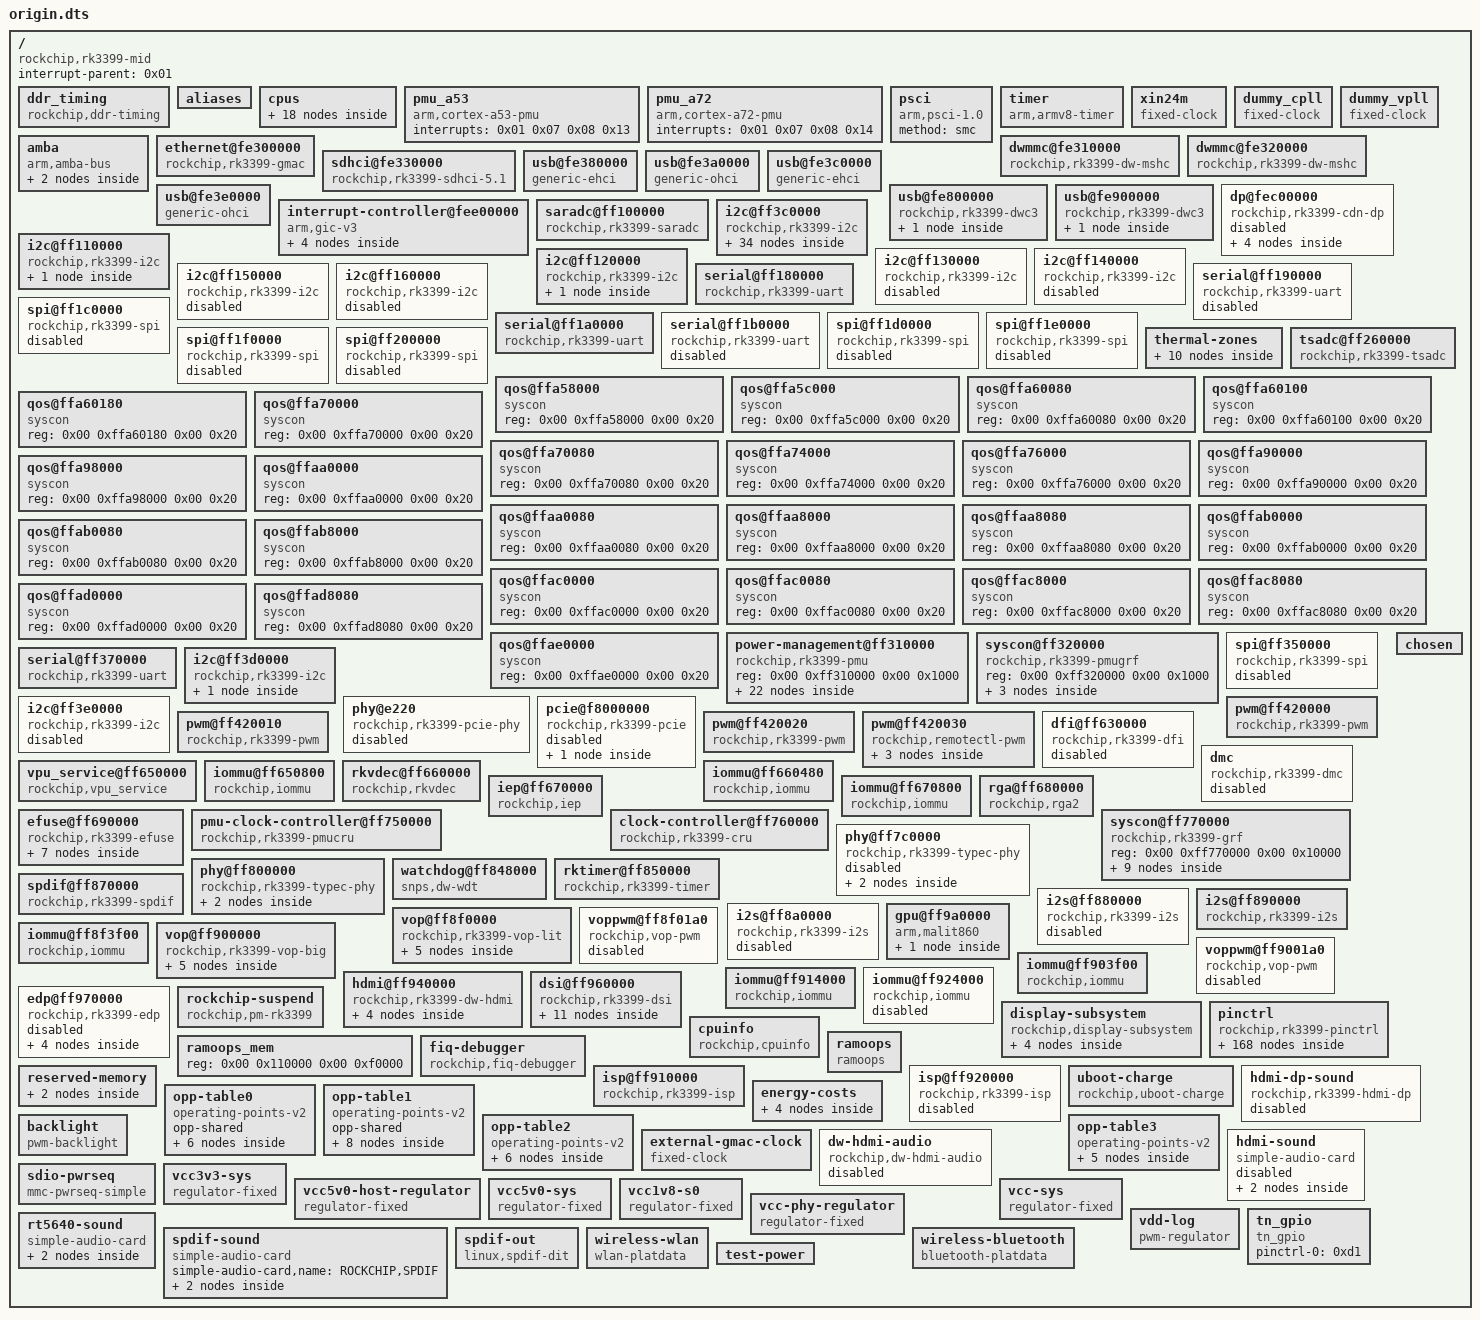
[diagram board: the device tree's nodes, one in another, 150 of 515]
/dts-v1/;

/ {
	compatible = "rockchip,rk3399-mid", "rockchip,rk3399";
	interrupt-parent = <0x01>;
	#address-cells = <0x02>;
	#size-cells = <0x02>;

	ddr_timing {
		compatible = "rockchip,ddr-timing";
		ddr3_speed_bin = <0x15>;
		pd_idle = <0x00>;
		sr_idle = <0x00>;
		sr_mc_gate_idle = <0x00>;
		srpd_lite_idle = <0x00>;
		standby_idle = <0x00>;
		dram_dll_dis_freq = <0x12c>;
		phy_dll_dis_freq = <0x7d>;
		ddr3_odt_dis_freq = <0x14d>;
		ddr3_drv = <0x28>;
		ddr3_odt = <0x78>;
		phy_ddr3_ca_drv = <0x28>;
		phy_ddr3_dq_drv = <0x28>;
		phy_ddr3_odt = <0xf0>;
		lpddr3_odt_dis_freq = <0x14d>;
		lpddr3_drv = <0x22>;
		lpddr3_odt = <0xf0>;
		phy_lpddr3_ca_drv = <0x28>;
		phy_lpddr3_dq_drv = <0x28>;
		phy_lpddr3_odt = <0xf0>;
		lpddr4_odt_dis_freq = <0x14d>;
		lpddr4_drv = <0x3c>;
		lpddr4_dq_odt = <0x28>;
		lpddr4_ca_odt = <0x28>;
		phy_lpddr4_ca_drv = <0x28>;
		phy_lpddr4_ck_cs_drv = <0x50>;
		phy_lpddr4_dq_drv = <0x50>;
		phy_lpddr4_odt = <0x3c>;
		linux,phandle = <0x89>;
		phandle = <0x89>;
	};

	aliases {
		i2c0 = "/i2c@ff3c0000";
		i2c1 = "/i2c@ff110000";
		i2c2 = "/i2c@ff120000";
		i2c3 = "/i2c@ff130000";
		i2c4 = "/i2c@ff3d0000";
		i2c5 = "/i2c@ff140000";
		i2c6 = "/i2c@ff150000";
		i2c7 = "/i2c@ff160000";
		i2c8 = "/i2c@ff3e0000";
		serial0 = "/serial@ff180000";
		serial1 = "/serial@ff190000";
		serial2 = "/serial@ff1a0000";
		serial3 = "/serial@ff1b0000";
		serial4 = "/serial@ff370000";
	};

	cpus {
		#address-cells = <0x02>;
		#size-cells = <0x00>;

		cpu-map {

			cluster0 {

				core0 {
					cpu = <0x02>;
				};

				core1 {
					cpu = <0x03>;
				};

				core2 {
					cpu = <0x04>;
				};

				core3 {
					cpu = <0x05>;
				};
			};

			cluster1 {

				core0 {
					cpu = <0x06>;
				};

				core1 {
					cpu = <0x07>;
				};
			};
		};

		cpu@0 {
			device_type = "cpu";
			compatible = "arm,cortex-a53", "arm,armv8";
			reg = <0x00 0x00>;
			enable-method = "psci";
			#cooling-cells = <0x02>;
			dynamic-power-coefficient = <0x64>;
			clocks = <0x08 0x08>;
			cpu-idle-states = <0x09 0x0a>;
			operating-points-v2 = <0x0b>;
			sched-energy-costs = <0x0c 0x0d>;
			cpu-supply = <0x0e>;
			linux,phandle = <0x02>;
			phandle = <0x02>;
		};

		cpu@1 {
			device_type = "cpu";
			compatible = "arm,cortex-a53", "arm,armv8";
			reg = <0x00 0x01>;
			enable-method = "psci";
			clocks = <0x08 0x08>;
			cpu-idle-states = <0x09 0x0a>;
			operating-points-v2 = <0x0b>;
			sched-energy-costs = <0x0c 0x0d>;
			cpu-supply = <0x0e>;
			linux,phandle = <0x03>;
			phandle = <0x03>;
		};

		cpu@2 {
			device_type = "cpu";
			compatible = "arm,cortex-a53", "arm,armv8";
			reg = <0x00 0x02>;
			enable-method = "psci";
			clocks = <0x08 0x08>;
			cpu-idle-states = <0x09 0x0a>;
			operating-points-v2 = <0x0b>;
			sched-energy-costs = <0x0c 0x0d>;
			cpu-supply = <0x0e>;
			linux,phandle = <0x04>;
			phandle = <0x04>;
		};

		cpu@3 {
			device_type = "cpu";
			compatible = "arm,cortex-a53", "arm,armv8";
			reg = <0x00 0x03>;
			enable-method = "psci";
			clocks = <0x08 0x08>;
			cpu-idle-states = <0x09 0x0a>;
			operating-points-v2 = <0x0b>;
			sched-energy-costs = <0x0c 0x0d>;
			cpu-supply = <0x0e>;
			linux,phandle = <0x05>;
			phandle = <0x05>;
		};

		cpu@100 {
			device_type = "cpu";
			compatible = "arm,cortex-a72", "arm,armv8";
			reg = <0x00 0x100>;
			enable-method = "psci";
			#cooling-cells = <0x02>;
			dynamic-power-coefficient = <0x1b4>;
			clocks = <0x08 0x09>;
			cpu-idle-states = <0x09 0x0a>;
			operating-points-v2 = <0x0f>;
			sched-energy-costs = <0x10 0x11>;
			cpu-supply = <0x12>;
			linux,phandle = <0x06>;
			phandle = <0x06>;
		};

		cpu@101 {
			device_type = "cpu";
			compatible = "arm,cortex-a72", "arm,armv8";
			reg = <0x00 0x101>;
			enable-method = "psci";
			clocks = <0x08 0x09>;
			cpu-idle-states = <0x09 0x0a>;
			operating-points-v2 = <0x0f>;
			sched-energy-costs = <0x10 0x11>;
			cpu-supply = <0x12>;
			linux,phandle = <0x07>;
			phandle = <0x07>;
		};

		idle-states {
			entry-method = "psci";

			cpu-sleep {
				compatible = "arm,idle-state";
				local-timer-stop;
				arm,psci-suspend-param = <0x10000>;
				entry-latency-us = <0x78>;
				exit-latency-us = <0xfa>;
				min-residency-us = <0x384>;
				linux,phandle = <0x09>;
				phandle = <0x09>;
			};

			cluster-sleep {
				compatible = "arm,idle-state";
				local-timer-stop;
				arm,psci-suspend-param = <0x1010000>;
				entry-latency-us = <0x190>;
				exit-latency-us = <0x1f4>;
				min-residency-us = <0x7d0>;
				linux,phandle = <0x0a>;
				phandle = <0x0a>;
			};
		};
	};

	pmu_a53 {
		compatible = "arm,cortex-a53-pmu";
		interrupts = <0x01 0x07 0x08 0x13>;
	};

	pmu_a72 {
		compatible = "arm,cortex-a72-pmu";
		interrupts = <0x01 0x07 0x08 0x14>;
	};

	psci {
		compatible = "arm,psci-1.0";
		method = "smc";
	};

	timer {
		compatible = "arm,armv8-timer";
		interrupts = <0x01 0x0d 0x08 0x00 0x01 0x0e 0x08 0x00 0x01 0x0b 0x08 0x00 0x01 0x0a 0x08 0x00>;
	};

	xin24m {
		compatible = "fixed-clock";
		clock-frequency = <0x16e3600>;
		clock-output-names = "xin24m";
		#clock-cells = <0x00>;
	};

	dummy_cpll {
		compatible = "fixed-clock";
		clock-frequency = <0x00>;
		clock-output-names = "dummy_cpll";
		#clock-cells = <0x00>;
	};

	dummy_vpll {
		compatible = "fixed-clock";
		clock-frequency = <0x00>;
		clock-output-names = "dummy_vpll";
		#clock-cells = <0x00>;
	};

	amba {
		compatible = "arm,amba-bus";
		#address-cells = <0x02>;
		#size-cells = <0x02>;
		ranges;

		dma-controller@ff6d0000 {
			compatible = "arm,pl330", "arm,primecell";
			reg = <0x00 0xff6d0000 0x00 0x4000>;
			interrupts = <0x00 0x05 0x04 0x00 0x00 0x06 0x04 0x00>;
			#dma-cells = <0x01>;
			clocks = <0x08 0xd3>;
			clock-names = "apb_pclk";
			peripherals-req-type-burst;
			linux,phandle = <0x92>;
			phandle = <0x92>;
		};

		dma-controller@ff6e0000 {
			compatible = "arm,pl330", "arm,primecell";
			reg = <0x00 0xff6e0000 0x00 0x4000>;
			interrupts = <0x00 0x07 0x04 0x00 0x00 0x08 0x04 0x00>;
			#dma-cells = <0x01>;
			clocks = <0x08 0xd4>;
			clock-names = "apb_pclk";
			peripherals-req-type-burst;
		};
	};

	ethernet@fe300000 {
		compatible = "rockchip,rk3399-gmac";
		reg = <0x00 0xfe300000 0x00 0x10000>;
		rockchip,grf = <0x15>;
		interrupts = <0x00 0x0c 0x04 0x00>;
		interrupt-names = "macirq";
		clocks = <0x08 0x69 0x08 0x67 0x08 0x68 0x08 0x66 0x08 0x6a 0x08 0xd5 0x08 0x166>;
		clock-names = "stmmaceth", "mac_clk_rx", "mac_clk_tx", "clk_mac_ref", "clk_mac_refout", "aclk_mac", "pclk_mac";
		resets = <0x08 0x89>;
		reset-names = "stmmaceth";
		power-domains = <0x16 0x16>;
		status = "okay";
		phy-supply = <0x17>;
		phy-mode = "rgmii";
		clock_in_out = "input";
		snps,reset-gpio = <0x18 0x0f 0x01>;
		snps,reset-active-low;
		snps,reset-delays-us = <0x00 0x2710 0xc350>;
		assigned-clocks = <0x08 0xa6>;
		assigned-clock-parents = <0x19>;
		pinctrl-names = "default", "sleep";
		pinctrl-0 = <0x1a>;
		pinctrl-1 = <0x1b>;
		tx_delay = <0x28>;
		rx_delay = <0x11>;
	};

	dwmmc@fe310000 {
		compatible = "rockchip,rk3399-dw-mshc", "rockchip,rk3288-dw-mshc";
		reg = <0x00 0xfe310000 0x00 0x4000>;
		interrupts = <0x00 0x40 0x04 0x00>;
		clock-freq-min-max = <0x30d40 0x5f5e100>;
		clocks = <0x08 0x1ee 0x08 0x4d 0x08 0x9c 0x08 0x9d>;
		clock-names = "biu", "ciu", "ciu-drive", "ciu-sample";
		fifo-depth = <0x100>;
		power-domains = <0x16 0x1c>;
		status = "okay";
		clock-frequency = <0x5f5e100>;
		supports-sdio;
		bus-width = <0x04>;
		disable-wp;
		cap-sd-highspeed;
		cap-sdio-irq;
		keep-power-in-suspend;
		mmc-pwrseq = <0x1c>;
		non-removable;
		num-slots = <0x01>;
		pinctrl-names = "default";
		pinctrl-0 = <0x1d 0x1e 0x1f>;
		sd-uhs-sdr104;
	};

	dwmmc@fe320000 {
		compatible = "rockchip,rk3399-dw-mshc", "rockchip,rk3288-dw-mshc";
		reg = <0x00 0xfe320000 0x00 0x4000>;
		interrupts = <0x00 0x41 0x04 0x00>;
		clock-freq-min-max = <0x186a0 0x5f5e100>;
		clocks = <0x08 0x1ce 0x08 0x4c 0x08 0x9a 0x08 0x9b>;
		clock-names = "biu", "ciu", "ciu-drive", "ciu-sample";
		fifo-depth = <0x100>;
		power-domains = <0x16 0x1b>;
		status = "okay";
		clock-frequency = <0x5f5e100>;
		supports-sd;
		bus-width = <0x04>;
		cap-mmc-highspeed;
		cap-sd-highspeed;
		disable-wp;
		num-slots = <0x01>;
		vqmmc-supply = <0x20>;
		pinctrl-names = "default";
		pinctrl-0 = <0x21 0x22 0x23 0x24>;
		card-detect-delay = <0x320>;
	};

	sdhci@fe330000 {
		compatible = "rockchip,rk3399-sdhci-5.1", "arasan,sdhci-5.1";
		reg = <0x00 0xfe330000 0x00 0x10000>;
		interrupts = <0x00 0x0b 0x04 0x00>;
		arasan,soc-ctl-syscon = <0x15>;
		assigned-clocks = <0x08 0x4e>;
		assigned-clock-rates = <0xbebc200>;
		clocks = <0x08 0x4e 0x08 0xf0>;
		clock-names = "clk_xin", "clk_ahb";
		clock-output-names = "emmc_cardclock";
		#clock-cells = <0x00>;
		phys = <0x25>;
		phy-names = "phy_arasan";
		power-domains = <0x16 0x17>;
		status = "okay";
		assigned-clock-parents = <0x08 0x05>;
		bus-width = <0x08>;
		mmc-hs400-1_8v;
		supports-emmc;
		non-removable;
		mmc-hs400-enhanced-strobe;
		linux,phandle = <0x90>;
		phandle = <0x90>;
	};

	usb@fe380000 {
		compatible = "generic-ehci";
		reg = <0x00 0xfe380000 0x00 0x20000>;
		interrupts = <0x00 0x1a 0x04 0x00>;
		clocks = <0x08 0x1c8 0x08 0x1c9 0x08 0xa8>;
		clock-names = "hclk_host0", "hclk_host0_arb", "usbphy0_480m";
		phys = <0x26>;
		phy-names = "usb";
		power-domains = <0x16 0x0e>;
		status = "okay";
	};

	usb@fe3a0000 {
		compatible = "generic-ohci";
		reg = <0x00 0xfe3a0000 0x00 0x20000>;
		interrupts = <0x00 0x1c 0x04 0x00>;
		clocks = <0x08 0x1c8 0x08 0x1c9 0x08 0xa8>;
		clock-names = "hclk_host0", "hclk_host0_arb", "usbphy0_480m";
		phys = <0x26>;
		phy-names = "usb";
		power-domains = <0x16 0x0e>;
		status = "okay";
	};

	usb@fe3c0000 {
		compatible = "generic-ehci";
		reg = <0x00 0xfe3c0000 0x00 0x20000>;
		interrupts = <0x00 0x1e 0x04 0x00>;
		clocks = <0x08 0x1ca 0x08 0x1cb 0x08 0xa9>;
		clock-names = "hclk_host1", "hclk_host1_arb", "usbphy1_480m";
		phys = <0x27>;
		phy-names = "usb";
		power-domains = <0x16 0x0e>;
		status = "okay";
	};

	usb@fe3e0000 {
		compatible = "generic-ohci";
		reg = <0x00 0xfe3e0000 0x00 0x20000>;
		interrupts = <0x00 0x20 0x04 0x00>;
		clocks = <0x08 0x1ca 0x08 0x1cb 0x08 0xa9>;
		clock-names = "hclk_host1", "hclk_host1_arb", "usbphy1_480m";
		phys = <0x27>;
		phy-names = "usb";
		power-domains = <0x16 0x0e>;
		status = "okay";
	};

	usb@fe800000 {
		compatible = "rockchip,rk3399-dwc3";
		clocks = <0x08 0x81 0x08 0x83 0x08 0xf6 0x08 0xf9>;
		clock-names = "ref_clk", "suspend_clk", "bus_clk", "grf_clk";
		power-domains = <0x16 0x18>;
		resets = <0x08 0x125>;
		reset-names = "usb3-otg";
		#address-cells = <0x02>;
		#size-cells = <0x02>;
		ranges;
		status = "okay";
		extcon = <0x28>;

		dwc3@fe800000 {
			compatible = "snps,dwc3";
			reg = <0x00 0xfe800000 0x00 0x100000>;
			interrupts = <0x00 0x69 0x04 0x00>;
			dr_mode = "otg";
			phys = <0x29>;
			phy-names = "usb2-phy";
			phy_type = "utmi_wide";
			snps,dis_enblslpm_quirk;
			snps,dis-u2-freeclk-exists-quirk;
			snps,dis_u2_susphy_quirk;
			snps,dis-del-phy-power-chg-quirk;
			snps,xhci-slow-suspend-quirk;
			status = "okay";
			maximum-speed = "high-speed";
		};
	};

	usb@fe900000 {
		compatible = "rockchip,rk3399-dwc3";
		clocks = <0x08 0x82 0x08 0x84 0x08 0xf7 0x08 0xf9>;
		clock-names = "ref_clk", "suspend_clk", "bus_clk", "grf_clk";
		power-domains = <0x16 0x18>;
		resets = <0x08 0x126>;
		reset-names = "usb3-otg";
		#address-cells = <0x02>;
		#size-cells = <0x02>;
		ranges;
		status = "okay";

		dwc3@fe900000 {
			compatible = "snps,dwc3";
			reg = <0x00 0xfe900000 0x00 0x100000>;
			interrupts = <0x00 0x6e 0x04 0x00>;
			dr_mode = "host";
			phys = <0x2a 0x2b>;
			phy-names = "usb2-phy", "usb3-phy";
			phy_type = "utmi_wide";
			snps,dis_enblslpm_quirk;
			snps,dis-u2-freeclk-exists-quirk;
			snps,dis_u2_susphy_quirk;
			snps,dis-del-phy-power-chg-quirk;
			snps,xhci-slow-suspend-quirk;
			status = "okay";
		};
	};

	dp@fec00000 {
		compatible = "rockchip,rk3399-cdn-dp";
		reg = <0x00 0xfec00000 0x00 0x100000>;
		interrupts = <0x00 0x09 0x04>;
		clocks = <0x08 0x72 0x08 0x175 0x08 0xa1 0x08 0x16f>;
		clock-names = "core-clk", "pclk", "spdif", "grf";
		assigned-clocks = <0x08 0x72>;
		assigned-clock-rates = <0x5f5e100>;
		power-domains = <0x16 0x15>;
		phys = <0x2c 0x2d>;
		resets = <0x08 0x103 0x08 0x148 0x08 0x14a 0x08 0xfd>;
		reset-names = "spdif", "dptx", "apb", "core";
		rockchip,grf = <0x15>;
		#address-cells = <0x01>;
		#size-cells = <0x00>;
		#sound-dai-cells = <0x01>;
		status = "disabled";
		linux,phandle = <0xc9>;
		phandle = <0xc9>;

		ports {
			#address-cells = <0x01>;
			#size-cells = <0x00>;

			port {
				#address-cells = <0x01>;
				#size-cells = <0x00>;

				endpoint@0 {
					reg = <0x00>;
					remote-endpoint = <0x2e>;
					status = "disabled";
					linux,phandle = <0xa2>;
					phandle = <0xa2>;
				};

				endpoint@1 {
					reg = <0x01>;
					remote-endpoint = <0x2f>;
					linux,phandle = <0x9c>;
					phandle = <0x9c>;
				};
			};
		};
	};

	interrupt-controller@fee00000 {
		compatible = "arm,gic-v3";
		#interrupt-cells = <0x04>;
		#address-cells = <0x02>;
		#size-cells = <0x02>;
		ranges;
		interrupt-controller;
		reg = <0x00 0xfee00000 0x00 0x10000 0x00 0xfef00000 0x00 0xc0000 0x00 0xfff00000 0x00 0x10000 0x00 0xfff10000 0x00 0x10000 0x00 0xfff20000 0x00 0x10000>;
		interrupts = <0x01 0x09 0x04 0x00>;
		linux,phandle = <0x01>;
		phandle = <0x01>;

		interrupt-controller@fee20000 {
			compatible = "arm,gic-v3-its";
			msi-controller;
			reg = <0x00 0xfee20000 0x00 0x20000>;
			linux,phandle = <0x80>;
			phandle = <0x80>;
		};

		ppi-partitions {

			interrupt-partition-0 {
				affinity = <0x02 0x03 0x04 0x05>;
				linux,phandle = <0x13>;
				phandle = <0x13>;
			};

			interrupt-partition-1 {
				affinity = <0x06 0x07>;
				linux,phandle = <0x14>;
				phandle = <0x14>;
			};
		};
	};

	saradc@ff100000 {
		compatible = "rockchip,rk3399-saradc";
		reg = <0x00 0xff100000 0x00 0x100>;
		interrupts = <0x00 0x3e 0x04 0x00>;
		#io-channel-cells = <0x01>;
		clocks = <0x08 0x50 0x08 0x165>;
		clock-names = "saradc", "apb_pclk";
		resets = <0x08 0xd4>;
		reset-names = "saradc-apb";
		status = "okay";
	};

	i2c@ff3c0000 {
		compatible = "rockchip,rk3399-i2c";
		reg = <0x00 0xff3c0000 0x00 0x1000>;
		clocks = <0x30 0x09 0x30 0x1b>;
		clock-names = "i2c", "pclk";
		interrupts = <0x00 0x39 0x04 0x00>;
		pinctrl-names = "default";
		pinctrl-0 = <0x31>;
		#address-cells = <0x01>;
		#size-cells = <0x00>;
		status = "okay";
		i2c-scl-rising-time-ns = <0xa8>;
		i2c-scl-falling-time-ns = <0x04>;
		clock-frequency = <0x61a80>;

		syr827@40 {
			compatible = "silergy,syr827";
			reg = <0x40>;
			regulator-compatible = "fan53555-reg";
			pinctrl-0 = <0x32>;
			vsel-gpios = <0x33 0x11 0x00>;
			regulator-name = "vdd_cpu_b";
			regulator-min-microvolt = <0xadf34>;
			regulator-max-microvolt = <0x16e360>;
			regulator-ramp-delay = <0x3e8>;
			fcs,suspend-voltage-selector = <0x01>;
			regulator-always-on;
			regulator-boot-on;
			vin-supply = <0x34>;
			linux,phandle = <0x12>;
			phandle = <0x12>;

			regulator-state-mem {
				regulator-off-in-suspend;
			};
		};

		syr828@41 {
			compatible = "silergy,syr828";
			reg = <0x41>;
			regulator-compatible = "fan53555-reg";
			pinctrl-0 = <0x35>;
			vsel-gpios = <0x33 0x0e 0x00>;
			regulator-name = "vdd_gpu";
			regulator-min-microvolt = <0xadf34>;
			regulator-max-microvolt = <0x16e360>;
			regulator-ramp-delay = <0x3e8>;
			fcs,suspend-voltage-selector = <0x01>;
			regulator-always-on;
			regulator-boot-on;
			vin-supply = <0x34>;
			regulator-initial-mode = <0x01>;
			linux,phandle = <0x97>;
			phandle = <0x97>;

			regulator-state-mem {
				regulator-off-in-suspend;
			};
		};

		pmic@1b {
			compatible = "rockchip,rk808";
			reg = <0x1b>;
			interrupt-parent = <0x33>;
			interrupts = <0x15 0x08>;
			pinctrl-names = "default";
			pinctrl-0 = <0x36>;
			rockchip,system-power-controller;
			wakeup-source;
			#clock-cells = <0x01>;
			clock-output-names = "xin32k", "rk808-clkout2";
			vcc1-supply = <0x34>;
			vcc2-supply = <0x34>;
			vcc3-supply = <0x34>;
			vcc4-supply = <0x34>;
			vcc6-supply = <0x34>;
			vcc7-supply = <0x34>;
			vcc8-supply = <0x37>;
			vcc9-supply = <0x34>;
			vcc10-supply = <0x34>;
			vcc11-supply = <0x34>;
			vcc12-supply = <0x37>;
			vddio-supply = <0x38>;
			linux,phandle = <0xcc>;
			phandle = <0xcc>;

			regulators {

				DCDC_REG1 {
					regulator-name = "vdd_center";
					regulator-min-microvolt = <0xb71b0>;
					regulator-max-microvolt = <0x149970>;
					regulator-ramp-delay = <0x1771>;
					regulator-always-on;
					regulator-boot-on;

					regulator-state-mem {
						regulator-off-in-suspend;
					};
				};

				DCDC_REG2 {
					regulator-name = "vdd_cpu_l";
					regulator-min-microvolt = <0xb71b0>;
					regulator-max-microvolt = <0x149970>;
					regulator-ramp-delay = <0x1771>;
					regulator-always-on;
					regulator-boot-on;
					linux,phandle = <0x0e>;
					phandle = <0x0e>;

					regulator-state-mem {
						regulator-off-in-suspend;
					};
				};

				DCDC_REG3 {
					regulator-name = "vcc_ddr";
					regulator-always-on;
					regulator-boot-on;

					regulator-state-mem {
						regulator-on-in-suspend;
					};
				};

				DCDC_REG4 {
					regulator-name = "vcc_1v8";
					regulator-min-microvolt = <0x1b7740>;
					regulator-max-microvolt = <0x1b7740>;
					regulator-always-on;
					regulator-boot-on;
					linux,phandle = <0x38>;
					phandle = <0x38>;

					regulator-state-mem {
						regulator-on-in-suspend;
						regulator-suspend-microvolt = <0x1b7740>;
					};
				};

				LDO_REG1 {
					regulator-name = "vcc1v8_dvp";
					regulator-min-microvolt = <0x1b7740>;
					regulator-max-microvolt = <0x1b7740>;
					regulator-always-on;
					regulator-boot-on;

					regulator-state-mem {
						regulator-on-in-suspend;
						regulator-suspend-microvolt = <0x1b7740>;
					};
				};

				LDO_REG2 {
					regulator-name = "vcca3v3_rtc";
					regulator-min-microvolt = <0x325aa0>;
					regulator-max-microvolt = <0x325aa0>;
					regulator-always-on;
					regulator-boot-on;

					regulator-state-mem {
						regulator-on-in-suspend;
						regulator-suspend-microvolt = <0x325aa0>;
					};
				};

				LDO_REG3 {
					regulator-name = "vcca_1v8";
					regulator-min-microvolt = <0x1b7740>;
					regulator-max-microvolt = <0x1b7740>;
					regulator-always-on;
					regulator-boot-on;

					regulator-state-mem {
						regulator-on-in-suspend;
						regulator-suspend-microvolt = <0x1b7740>;
					};
				};

				LDO_REG4 {
					regulator-name = "vcc_sd";
					regulator-min-microvolt = <0x1b7740>;
					regulator-max-microvolt = <0x325aa0>;
					regulator-always-on;
					regulator-boot-on;
					linux,phandle = <0x20>;
					phandle = <0x20>;

					regulator-state-mem {
						regulator-on-in-suspend;
						regulator-suspend-microvolt = <0x325aa0>;
					};
				};

				LDO_REG5 {
					regulator-name = "vcc3v0_sd";
					regulator-min-microvolt = <0x2dc6c0>;
					regulator-max-microvolt = <0x2dc6c0>;
					regulator-always-on;
					regulator-boot-on;

					regulator-state-mem {
						regulator-on-in-suspend;
						regulator-suspend-microvolt = <0x2dc6c0>;
					};
				};

				LDO_REG6 {
					regulator-name = "vcc_1v5";
					regulator-min-microvolt = <0x16e360>;
					regulator-max-microvolt = <0x16e360>;
					regulator-always-on;
					regulator-boot-on;

					regulator-state-mem {
						regulator-on-in-suspend;
						regulator-suspend-microvolt = <0x16e360>;
					};
				};

				LDO_REG7 {
					regulator-name = "vcca0v9_hdmi";
					regulator-min-microvolt = <0x1b7740>;
					regulator-max-microvolt = <0x1b7740>;
					regulator-always-on;
					regulator-boot-on;

					regulator-state-mem {
						regulator-on-in-suspend;
						regulator-suspend-microvolt = <0x1b7740>;
					};
				};

				LDO_REG8 {
					regulator-name = "vcc_3v0";
					regulator-min-microvolt = <0x2dc6c0>;
					regulator-max-microvolt = <0x2dc6c0>;
					regulator-always-on;
					regulator-boot-on;
					linux,phandle = <0x8f>;
					phandle = <0x8f>;

					regulator-state-mem {
						regulator-on-in-suspend;
						regulator-suspend-microvolt = <0x2dc6c0>;
					};
				};

				SWITCH_REG1 {
					regulator-name = "vcc3v3_s3";
					regulator-always-on;
					regulator-boot-on;

					regulator-state-mem {
						regulator-on-in-suspend;
					};
				};

				SWITCH_REG2 {
					regulator-name = "vcc3v3_s0";
					regulator-always-on;
					regulator-boot-on;

					regulator-state-mem {
						regulator-on-in-suspend;
					};
				};
			};
		};
	};

	i2c@ff110000 {
		compatible = "rockchip,rk3399-i2c";
		reg = <0x00 0xff110000 0x00 0x1000>;
		clocks = <0x08 0x41 0x08 0x155>;
		clock-names = "i2c", "pclk";
		interrupts = <0x00 0x3b 0x04 0x00>;
		pinctrl-names = "default";
		pinctrl-0 = <0x39>;
		#address-cells = <0x01>;
		#size-cells = <0x00>;
		status = "okay";
		i2c-scl-rising-time-ns = <0x8c>;
		i2c-scl-falling-time-ns = <0x1e>;

		rt5640@1c {
			#sound-dai-cells = <0x00>;
			compatible = "realtek,rt5640";
			reg = <0x1c>;
			clocks = <0x08 0x59>;
			clock-names = "mclk";
			realtek,in1-differential;
			linux,phandle = <0xd3>;
			phandle = <0xd3>;
		};
	};

	i2c@ff120000 {
		compatible = "rockchip,rk3399-i2c";
		reg = <0x00 0xff120000 0x00 0x1000>;
		clocks = <0x08 0x42 0x08 0x156>;
		clock-names = "i2c", "pclk";
		interrupts = <0x00 0x23 0x04 0x00>;
		pinctrl-names = "default";
		pinctrl-0 = <0x3a>;
		#address-cells = <0x01>;
		#size-cells = <0x00>;
		status = "okay";

		rtc@51 {
			compatible = "rtc,hym8563";
			reg = <0x51>;
		};
	};

	i2c@ff130000 {
		compatible = "rockchip,rk3399-i2c";
		reg = <0x00 0xff130000 0x00 0x1000>;
		clocks = <0x08 0x43 0x08 0x157>;
		clock-names = "i2c", "pclk";
		interrupts = <0x00 0x22 0x04 0x00>;
		pinctrl-names = "default";
		pinctrl-0 = <0x3b>;
		#address-cells = <0x01>;
		#size-cells = <0x00>;
		status = "disabled";
	};

	i2c@ff140000 {
		compatible = "rockchip,rk3399-i2c";
		reg = <0x00 0xff140000 0x00 0x1000>;
		clocks = <0x08 0x44 0x08 0x158>;
		clock-names = "i2c", "pclk";
		interrupts = <0x00 0x26 0x04 0x00>;
		pinctrl-names = "default";
		pinctrl-0 = <0x3c>;
		#address-cells = <0x01>;
		#size-cells = <0x00>;
		status = "disabled";
	};

	i2c@ff150000 {
		compatible = "rockchip,rk3399-i2c";
		reg = <0x00 0xff150000 0x00 0x1000>;
		clocks = <0x08 0x45 0x08 0x159>;
		clock-names = "i2c", "pclk";
		interrupts = <0x00 0x25 0x04 0x00>;
		pinctrl-names = "default";
		pinctrl-0 = <0x3d>;
		#address-cells = <0x01>;
		#size-cells = <0x00>;
		status = "disabled";
	};

	i2c@ff160000 {
		compatible = "rockchip,rk3399-i2c";
		reg = <0x00 0xff160000 0x00 0x1000>;
		clocks = <0x08 0x46 0x08 0x15a>;
		clock-names = "i2c", "pclk";
		interrupts = <0x00 0x24 0x04 0x00>;
		pinctrl-names = "default";
		pinctrl-0 = <0x3e>;
		#address-cells = <0x01>;
		#size-cells = <0x00>;
		status = "disabled";
	};

	serial@ff180000 {
		compatible = "rockchip,rk3399-uart", "snps,dw-apb-uart";
		reg = <0x00 0xff180000 0x00 0x100>;
		clocks = <0x08 0x51 0x08 0x160>;
		clock-names = "baudclk", "apb_pclk";
		interrupts = <0x00 0x63 0x04 0x00>;
		reg-shift = <0x02>;
		reg-io-width = <0x04>;
		pinctrl-names = "default";
		pinctrl-0 = <0x3f 0x40>;
		status = "okay";
		assigned-clocks = <0x08 0xac>;
		assigned-clock-parents = <0x08 0x05>;
	};

	serial@ff190000 {
		compatible = "rockchip,rk3399-uart", "snps,dw-apb-uart";
		reg = <0x00 0xff190000 0x00 0x100>;
		clocks = <0x08 0x52 0x08 0x161>;
		clock-names = "baudclk", "apb_pclk";
		interrupts = <0x00 0x62 0x04 0x00>;
		reg-shift = <0x02>;
		reg-io-width = <0x04>;
		pinctrl-names = "default";
		pinctrl-0 = <0x41>;
		status = "disabled";
		assigned-clocks = <0x08 0xad>;
		assigned-clock-parents = <0x08 0x05>;
	};

	serial@ff1a0000 {
		compatible = "rockchip,rk3399-uart", "snps,dw-apb-uart";
		reg = <0x00 0xff1a0000 0x00 0x100>;
		clocks = <0x08 0x53 0x08 0x162>;
		clock-names = "baudclk", "apb_pclk";
		interrupts = <0x00 0x64 0x04 0x00>;
		reg-shift = <0x02>;
		reg-io-width = <0x04>;
		pinctrl-names = "default";
		pinctrl-0 = <0x42>;
		status = "okay";
		assigned-clocks = <0x08 0xad>;
		assigned-clock-parents = <0x08 0x05>;
	};

	serial@ff1b0000 {
		compatible = "rockchip,rk3399-uart", "snps,dw-apb-uart";
		reg = <0x00 0xff1b0000 0x00 0x100>;
		clocks = <0x08 0x54 0x08 0x163>;
		clock-names = "baudclk", "apb_pclk";
		interrupts = <0x00 0x65 0x04 0x00>;
		reg-shift = <0x02>;
		reg-io-width = <0x04>;
		pinctrl-names = "default";
		pinctrl-0 = <0x43 0x44 0x45>;
		status = "disabled";
		assigned-clocks = <0x08 0xad>;
		assigned-clock-parents = <0x08 0x05>;
	};

	spi@ff1c0000 {
		compatible = "rockchip,rk3399-spi", "rockchip,rk3066-spi";
		reg = <0x00 0xff1c0000 0x00 0x1000>;
		clocks = <0x08 0x47 0x08 0x15b>;
		clock-names = "spiclk", "apb_pclk";
		interrupts = <0x00 0x44 0x04 0x00>;
		pinctrl-names = "default";
		pinctrl-0 = <0x46 0x47 0x48 0x49>;
		#address-cells = <0x01>;
		#size-cells = <0x00>;
		status = "disabled";
	};

	spi@ff1d0000 {
		compatible = "rockchip,rk3399-spi", "rockchip,rk3066-spi";
		reg = <0x00 0xff1d0000 0x00 0x1000>;
		clocks = <0x08 0x48 0x08 0x15c>;
		clock-names = "spiclk", "apb_pclk";
		interrupts = <0x00 0x35 0x04 0x00>;
		pinctrl-names = "default";
		pinctrl-0 = <0x4a 0x4b 0x4c 0x4d>;
		#address-cells = <0x01>;
		#size-cells = <0x00>;
		status = "disabled";
	};

	spi@ff1e0000 {
		compatible = "rockchip,rk3399-spi", "rockchip,rk3066-spi";
		reg = <0x00 0xff1e0000 0x00 0x1000>;
		clocks = <0x08 0x49 0x08 0x15d>;
		clock-names = "spiclk", "apb_pclk";
		interrupts = <0x00 0x34 0x04 0x00>;
		pinctrl-names = "default";
		pinctrl-0 = <0x4e 0x4f 0x50 0x51>;
		#address-cells = <0x01>;
		#size-cells = <0x00>;
		status = "disabled";
	};

	spi@ff1f0000 {
		compatible = "rockchip,rk3399-spi", "rockchip,rk3066-spi";
		reg = <0x00 0xff1f0000 0x00 0x1000>;
		clocks = <0x08 0x4a 0x08 0x15e>;
		clock-names = "spiclk", "apb_pclk";
		interrupts = <0x00 0x43 0x04 0x00>;
		pinctrl-names = "default";
		pinctrl-0 = <0x52 0x53 0x54 0x55>;
		#address-cells = <0x01>;
		#size-cells = <0x00>;
		status = "disabled";
	};

	spi@ff200000 {
		compatible = "rockchip,rk3399-spi", "rockchip,rk3066-spi";
		reg = <0x00 0xff200000 0x00 0x1000>;
		clocks = <0x08 0x4b 0x08 0x15f>;
		clock-names = "spiclk", "apb_pclk";
		interrupts = <0x00 0x84 0x04 0x00>;
		pinctrl-names = "default";
		pinctrl-0 = <0x56 0x57 0x58 0x59>;
		#address-cells = <0x01>;
		#size-cells = <0x00>;
		status = "disabled";
	};

	thermal-zones {

		soc-thermal {
			polling-delay-passive = <0x14>;
			polling-delay = <0x3e8>;
			sustainable-power = <0x3e8>;
			thermal-sensors = <0x5a 0x00>;

			trips {

				trip-point@0 {
					temperature = <0x14c08>;
					hysteresis = <0x7d0>;
					type = "passive";
				};

				trip-point@1 {
					temperature = <0x186a0>;
					hysteresis = <0x7d0>;
					type = "passive";
					linux,phandle = <0x5b>;
					phandle = <0x5b>;
				};

				soc-crit {
					temperature = <0x19a28>;
					hysteresis = <0x7d0>;
					type = "critical";
				};
			};

			cooling-maps {

				map0 {
					trip = <0x5b>;
					cooling-device = <0x02 0xffffffff 0xffffffff>;
					contribution = <0x1000>;
				};

				map1 {
					trip = <0x5b>;
					cooling-device = <0x06 0xffffffff 0xffffffff>;
					contribution = <0x400>;
				};

				map2 {
					trip = <0x5b>;
					cooling-device = <0x5c 0xffffffff 0xffffffff>;
					contribution = <0x1000>;
				};
			};
		};

		gpu-thermal {
			polling-delay-passive = <0x64>;
			polling-delay = <0x3e8>;
			thermal-sensors = <0x5a 0x01>;
		};
	};

	tsadc@ff260000 {
		compatible = "rockchip,rk3399-tsadc";
		reg = <0x00 0xff260000 0x00 0x100>;
		interrupts = <0x00 0x61 0x04 0x00>;
		rockchip,grf = <0x15>;
		clocks = <0x08 0x4f 0x08 0x164>;
		clock-names = "tsadc", "apb_pclk";
		assigned-clocks = <0x08 0x4f>;
		assigned-clock-rates = <0xb71b0>;
		resets = <0x08 0xe8>;
		reset-names = "tsadc-apb";
		pinctrl-names = "init", "default", "sleep";
		pinctrl-0 = <0x5d>;
		pinctrl-1 = <0x5e>;
		pinctrl-2 = <0x5d>;
		#thermal-sensor-cells = <0x01>;
		rockchip,hw-tshut-temp = <0x1adb0>;
		status = "okay";
		rockchip,hw-tshut-mode = <0x01>;
		rockchip,hw-tshut-polarity = <0x01>;
		linux,phandle = <0x5a>;
		phandle = <0x5a>;
	};

	qos@ffa58000 {
		compatible = "syscon";
		reg = <0x00 0xffa58000 0x00 0x20>;
		linux,phandle = <0x66>;
		phandle = <0x66>;
	};

	qos@ffa5c000 {
		compatible = "syscon";
		reg = <0x00 0xffa5c000 0x00 0x20>;
		linux,phandle = <0x67>;
		phandle = <0x67>;
	};

	qos@ffa60080 {
		compatible = "syscon";
		reg = <0x00 0xffa60080 0x00 0x20>;
		linux,phandle = <0x69>;
		phandle = <0x69>;
	};

	qos@ffa60100 {
		compatible = "syscon";
		reg = <0x00 0xffa60100 0x00 0x20>;
		linux,phandle = <0x6a>;
		phandle = <0x6a>;
	};

	qos@ffa60180 {
		compatible = "syscon";
		reg = <0x00 0xffa60180 0x00 0x20>;
		linux,phandle = <0x6b>;
		phandle = <0x6b>;
	};

	qos@ffa70000 {
		compatible = "syscon";
		reg = <0x00 0xffa70000 0x00 0x20>;
		linux,phandle = <0x6e>;
		phandle = <0x6e>;
	};

	qos@ffa70080 {
		compatible = "syscon";
		reg = <0x00 0xffa70080 0x00 0x20>;
		linux,phandle = <0x6f>;
		phandle = <0x6f>;
	};

	qos@ffa74000 {
		compatible = "syscon";
		reg = <0x00 0xffa74000 0x00 0x20>;
		linux,phandle = <0x6c>;
		phandle = <0x6c>;
	};

	qos@ffa76000 {
		compatible = "syscon";
		reg = <0x00 0xffa76000 0x00 0x20>;
		linux,phandle = <0x6d>;
		phandle = <0x6d>;
	};

	qos@ffa90000 {
		compatible = "syscon";
		reg = <0x00 0xffa90000 0x00 0x20>;
		linux,phandle = <0x70>;
		phandle = <0x70>;
	};

	qos@ffa98000 {
		compatible = "syscon";
		reg = <0x00 0xffa98000 0x00 0x20>;
		linux,phandle = <0x5f>;
		phandle = <0x5f>;
	};

	qos@ffaa0000 {
		compatible = "syscon";
		reg = <0x00 0xffaa0000 0x00 0x20>;
		linux,phandle = <0x71>;
		phandle = <0x71>;
	};

	qos@ffaa0080 {
		compatible = "syscon";
		reg = <0x00 0xffaa0080 0x00 0x20>;
		linux,phandle = <0x72>;
		phandle = <0x72>;
	};

	qos@ffaa8000 {
		compatible = "syscon";
		reg = <0x00 0xffaa8000 0x00 0x20>;
		linux,phandle = <0x73>;
		phandle = <0x73>;
	};

	qos@ffaa8080 {
		compatible = "syscon";
		reg = <0x00 0xffaa8080 0x00 0x20>;
		linux,phandle = <0x74>;
		phandle = <0x74>;
	};

	qos@ffab0000 {
		compatible = "syscon";
		reg = <0x00 0xffab0000 0x00 0x20>;
		linux,phandle = <0x60>;
		phandle = <0x60>;
	};

	qos@ffab0080 {
		compatible = "syscon";
		reg = <0x00 0xffab0080 0x00 0x20>;
		linux,phandle = <0x61>;
		phandle = <0x61>;
	};

	qos@ffab8000 {
		compatible = "syscon";
		reg = <0x00 0xffab8000 0x00 0x20>;
		linux,phandle = <0x62>;
		phandle = <0x62>;
	};

	qos@ffac0000 {
		compatible = "syscon";
		reg = <0x00 0xffac0000 0x00 0x20>;
		linux,phandle = <0x63>;
		phandle = <0x63>;
	};

	qos@ffac0080 {
		compatible = "syscon";
		reg = <0x00 0xffac0080 0x00 0x20>;
		linux,phandle = <0x64>;
		phandle = <0x64>;
	};

	qos@ffac8000 {
		compatible = "syscon";
		reg = <0x00 0xffac8000 0x00 0x20>;
		linux,phandle = <0x75>;
		phandle = <0x75>;
	};

	qos@ffac8080 {
		compatible = "syscon";
		reg = <0x00 0xffac8080 0x00 0x20>;
		linux,phandle = <0x76>;
		phandle = <0x76>;
	};

	qos@ffad0000 {
		compatible = "syscon";
		reg = <0x00 0xffad0000 0x00 0x20>;
		linux,phandle = <0x77>;
		phandle = <0x77>;
	};

	qos@ffad8080 {
		compatible = "syscon";
		reg = <0x00 0xffad8080 0x00 0x20>;
		linux,phandle = <0x68>;
		phandle = <0x68>;
	};

	qos@ffae0000 {
		compatible = "syscon";
		reg = <0x00 0xffae0000 0x00 0x20>;
		linux,phandle = <0x65>;
		phandle = <0x65>;
	};

	power-management@ff310000 {
		compatible = "rockchip,rk3399-pmu", "syscon", "simple-mfd";
		reg = <0x00 0xff310000 0x00 0x1000>;

		power-controller {
			compatible = "rockchip,rk3399-power-controller";
			#power-domain-cells = <0x01>;
			#address-cells = <0x01>;
			#size-cells = <0x00>;
			linux,phandle = <0x16>;
			phandle = <0x16>;

			pd_iep@34 {
				reg = <0x22>;
				clocks = <0x08 0xe1 0x08 0x1dd>;
				pm_qos = <0x5f>;
			};

			pd_rga@33 {
				reg = <0x21>;
				clocks = <0x08 0xdc 0x08 0x1e5>;
				pm_qos = <0x60 0x61>;
			};

			pd_vcodec@31 {
				reg = <0x1f>;
				clocks = <0x08 0xeb 0x08 0x1ea>;
				pm_qos = <0x62>;
			};

			pd_vdu@32 {
				reg = <0x20>;
				clocks = <0x08 0xed 0x08 0x1ec>;
				pm_qos = <0x63 0x64>;
			};

			pd_gpu@35 {
				reg = <0x23>;
				clocks = <0x08 0xd0>;
				pm_qos = <0x65>;
			};

			pd_edp@25 {
				reg = <0x19>;
				clocks = <0x08 0x16c>;
			};

			pd_emmc@23 {
				reg = <0x17>;
				clocks = <0x08 0xf0>;
				pm_qos = <0x66>;
			};

			pd_gmac@22 {
				reg = <0x16>;
				clocks = <0x08 0xd5 0x08 0x166>;
				pm_qos = <0x67>;
			};

			pd_perihp@14 {
				reg = <0x0e>;
				#address-cells = <0x01>;
				#size-cells = <0x00>;
				clocks = <0x08 0xc0>;
				pm_qos = <0x68 0x69 0x6a 0x6b>;

				pd_sd@27 {
					reg = <0x1b>;
					clocks = <0x08 0x1ce 0x08 0x4c>;
					pm_qos = <0x6c>;
				};
			};

			pd_sdioaudio@28 {
				reg = <0x1c>;
				clocks = <0x08 0x1ee>;
				pm_qos = <0x6d>;
			};

			pd_usb3@24 {
				reg = <0x18>;
				clocks = <0x08 0xf4>;
				pm_qos = <0x6e 0x6f>;
			};

			pd_vio@15 {
				reg = <0x0f>;
				#address-cells = <0x01>;
				#size-cells = <0x00>;

				pd_hdcp@21 {
					reg = <0x15>;
					clocks = <0x08 0xde 0x08 0x1e7 0x08 0x172>;
					pm_qos = <0x70>;
				};

				pd_isp0@19 {
					reg = <0x13>;
					clocks = <0x08 0xe5 0x08 0x1df>;
					pm_qos = <0x71 0x72>;
				};

				pd_isp1@20 {
					reg = <0x14>;
					clocks = <0x08 0xe6 0x08 0x1e0>;
					pm_qos = <0x73 0x74>;
				};

				pd_tcpc0@RK3399_PD_TCPC0 {
					reg = <0x08>;
					clocks = <0x08 0x7e 0x08 0x7d>;
				};

				pd_tcpc1@RK3399_PD_TCPC1 {
					reg = <0x09>;
					clocks = <0x08 0x80 0x08 0x7f>;
				};

				pd_vo@16 {
					reg = <0x10>;
					#address-cells = <0x01>;
					#size-cells = <0x00>;

					pd_vopb@17 {
						reg = <0x11>;
						clocks = <0x08 0xd9 0x08 0x1d9>;
						pm_qos = <0x75 0x76>;
					};

					pd_vopl@18 {
						reg = <0x12>;
						clocks = <0x08 0xdb 0x08 0x1db>;
						pm_qos = <0x77>;
					};
				};
			};
		};
	};

	syscon@ff320000 {
		compatible = "rockchip,rk3399-pmugrf", "syscon", "simple-mfd";
		reg = <0x00 0xff320000 0x00 0x1000>;
		#address-cells = <0x01>;
		#size-cells = <0x01>;
		linux,phandle = <0x87>;
		phandle = <0x87>;

		io-domains {
			compatible = "rockchip,rk3399-pmu-io-voltage-domain";
			status = "okay";
			pmu1830-supply = <0x38>;
		};

		reboot-mode {
			compatible = "syscon-reboot-mode";
			offset = <0x300>;
			mode-bootloader = <0x5242c301>;
			mode-charge = <0x5242c30b>;
			mode-fastboot = <0x5242c309>;
			mode-loader = <0x5242c301>;
			mode-normal = <0x5242c300>;
			mode-recovery = <0x5242c303>;
			mode-ums = <0x5242c30c>;
		};

		pmu-pvtm {
			compatible = "rockchip,rk3399-pmu-pvtm";
			clocks = <0x30 0x07>;
			clock-names = "pmu";
			status = "okay";
		};
	};

	spi@ff350000 {
		compatible = "rockchip,rk3399-spi", "rockchip,rk3066-spi";
		reg = <0x00 0xff350000 0x00 0x1000>;
		clocks = <0x30 0x03 0x30 0x1f>;
		clock-names = "spiclk", "apb_pclk";
		interrupts = <0x00 0x3c 0x04 0x00>;
		pinctrl-names = "default";
		pinctrl-0 = <0x78 0x79 0x7a 0x7b>;
		#address-cells = <0x01>;
		#size-cells = <0x00>;
		status = "disabled";
	};

	serial@ff370000 {
		compatible = "rockchip,rk3399-uart", "snps,dw-apb-uart";
		reg = <0x00 0xff370000 0x00 0x100>;
		clocks = <0x30 0x06 0x30 0x22>;
		clock-names = "baudclk", "apb_pclk";
		interrupts = <0x00 0x66 0x04 0x00>;
		reg-shift = <0x02>;
		reg-io-width = <0x04>;
		pinctrl-names = "default";
		pinctrl-0 = <0x7c>;
		status = "okay";
		assigned-clocks = <0x08 0xad>;
		assigned-clock-parents = <0x08 0x05>;
		current-speed = <0x2580>;
		no-loopback-test;
	};

	i2c@ff3d0000 {
		compatible = "rockchip,rk3399-i2c";
		reg = <0x00 0xff3d0000 0x00 0x1000>;
		clocks = <0x30 0x0a 0x30 0x1c>;
		clock-names = "i2c", "pclk";
		interrupts = <0x00 0x38 0x04 0x00>;
		pinctrl-names = "default";
		pinctrl-0 = <0x7d>;
		#address-cells = <0x01>;
		#size-cells = <0x00>;
		status = "okay";

		fusb30x@22 {
			compatible = "fairchild,fusb302";
			reg = <0x22>;
			pinctrl-names = "default";
			pinctrl-0 = <0x7e>;
			vbus-5v-gpios = <0x33 0x03 0x01>;
			int-n-gpios = <0x33 0x02 0x00>;
			status = "disabled";
		};
	};

	i2c@ff3e0000 {
		compatible = "rockchip,rk3399-i2c";
		reg = <0x00 0xff3e0000 0x00 0x1000>;
		clocks = <0x30 0x0b 0x30 0x1d>;
		clock-names = "i2c", "pclk";
		interrupts = <0x00 0x3a 0x04 0x00>;
		pinctrl-names = "default";
		pinctrl-0 = <0x7f>;
		#address-cells = <0x01>;
		#size-cells = <0x00>;
		status = "disabled";
	};

	phy@e220 {
		compatible = "rockchip,rk3399-pcie-phy";
		#phy-cells = <0x00>;
		rockchip,grf = <0x15>;
		clocks = <0x08 0x8a>;
		clock-names = "refclk";
		resets = <0x08 0x87>;
		reset-names = "phy";
		status = "disabled";
		linux,phandle = <0x82>;
		phandle = <0x82>;
	};

	pcie@f8000000 {
		compatible = "rockchip,rk3399-pcie";
		#address-cells = <0x03>;
		#size-cells = <0x02>;
		aspm-no-l0s;
		clocks = <0x08 0xc5 0x08 0xc4 0x08 0x147 0x08 0xa0>;
		clock-names = "aclk", "aclk-perf", "hclk", "pm";
		bus-range = <0x00 0x01>;
		max-link-speed = <0x01>;
		linux,pci-domain = <0x00>;
		msi-map = <0x00 0x80 0x00 0x1000>;
		interrupts = <0x00 0x31 0x04 0x00 0x00 0x32 0x04 0x00 0x00 0x33 0x04 0x00>;
		interrupt-names = "sys", "legacy", "client";
		#interrupt-cells = <0x01>;
		interrupt-map-mask = <0x00 0x00 0x00 0x07>;
		interrupt-map = <0x00 0x00 0x00 0x01 0x81 0x00 0x00 0x00 0x00 0x02 0x81 0x01 0x00 0x00 0x00 0x03 0x81 0x02 0x00 0x00 0x00 0x04 0x81 0x03>;
		phys = <0x82>;
		phy-names = "pcie-phy";
		ranges = <0x82000000 0x00 0xfa000000 0x00 0xfa000000 0x00 0x600000 0x81000000 0x00 0xfa600000 0x00 0xfa600000 0x00 0x100000>;
		reg = <0x00 0xf8000000 0x00 0x2000000 0x00 0xfd000000 0x00 0x1000000>;
		reg-names = "axi-base", "apb-base";
		resets = <0x08 0x82 0x08 0x83 0x08 0x84 0x08 0x85 0x08 0x86 0x08 0x81 0x08 0x80>;
		reset-names = "core", "mgmt", "mgmt-sticky", "pipe", "pm", "pclk", "aclk";
		status = "disabled";

		interrupt-controller {
			interrupt-controller;
			#address-cells = <0x00>;
			#interrupt-cells = <0x01>;
			linux,phandle = <0x81>;
			phandle = <0x81>;
		};
	};

	pwm@ff420000 {
		compatible = "rockchip,rk3399-pwm", "rockchip,rk3288-pwm";
		reg = <0x00 0xff420000 0x00 0x10>;
		#pwm-cells = <0x03>;
		pinctrl-names = "default";
		pinctrl-0 = <0x83>;
		clocks = <0x30 0x1e>;
		clock-names = "pwm";
		status = "okay";
		linux,phandle = <0xca>;
		phandle = <0xca>;
	};

	pwm@ff420010 {
		compatible = "rockchip,rk3399-pwm", "rockchip,rk3288-pwm";
		reg = <0x00 0xff420010 0x00 0x10>;
		#pwm-cells = <0x03>;
		pinctrl-names = "default";
		pinctrl-0 = <0x84>;
		clocks = <0x30 0x1e>;
		clock-names = "pwm";
		status = "okay";
	};

	pwm@ff420020 {
		compatible = "rockchip,rk3399-pwm", "rockchip,rk3288-pwm";
		reg = <0x00 0xff420020 0x00 0x10>;
		#pwm-cells = <0x03>;
		pinctrl-names = "default";
		pinctrl-0 = <0x85>;
		clocks = <0x30 0x1e>;
		clock-names = "pwm";
		status = "okay";
		linux,phandle = <0xd0>;
		phandle = <0xd0>;
	};

	pwm@ff420030 {
		compatible = "rockchip,remotectl-pwm";
		reg = <0x00 0xff420030 0x00 0x10>;
		#pwm-cells = <0x03>;
		pinctrl-names = "default";
		pinctrl-0 = <0x86>;
		clocks = <0x30 0x1e>;
		clock-names = "pwm";
		status = "okay";
		interrupts = <0x00 0x3d 0x04 0x00>;
		remote_pwm_id = <0x03>;
		handle_cpu_id = <0x01>;

		ir_key1 {
			rockchip,usercode = <0x4040>;
			rockchip,key_table = <0xf2 0xe8 0xba 0x9e 0xf4 0x67 0xf1 0x6c 0xef 0x69 0xee 0x6a 0xbd 0x66 0xea 0x73 0xe3 0x72 0xe2 0xd9 0xb2 0x74 0xbc 0x71 0xec 0x8b 0xbf 0x190 0xe0 0x191 0xe1 0x192 0xe9 0xb7 0xe6 0xf8 0xe8 0xb9 0xe7 0xba 0xf0 0x184 0xbe 0x175>;
		};

		ir_key2 {
			rockchip,usercode = <0xff00>;
			rockchip,key_table = <0xf9 0x66 0xbf 0x9e 0xfb 0x8b 0xaa 0xe8 0xb9 0x67 0xe9 0x6c 0xb8 0x69 0xea 0x6a 0xeb 0x72 0xef 0x73 0xf7 0x71 0xe7 0x74 0xfc 0x74 0xa9 0x72 0xa8 0x72 0xe0 0x72 0xa5 0x72 0xab 0xb7 0xb7 0x184 0xe8 0x184 0xf8 0xb8 0xaf 0xb9 0xed 0x72 0xee 0xba 0xb3 0x72 0xf1 0x72 0xf2 0x72 0xf3 0xd9 0xb4 0x72 0xbe 0xd9>;
		};

		ir_key3 {
			rockchip,usercode = <0x1dcc>;
			rockchip,key_table = <0xee 0xe8 0xf0 0x9e 0xf8 0x67 0xbb 0x6c 0xef 0x69 0xed 0x6a 0xfc 0x66 0xf1 0x73 0xfd 0x72 0xb7 0xd9 0xff 0x74 0xf3 0x71 0xbf 0x8b 0xf9 0x191 0xf5 0x192 0xb3 0x184 0xbe 0x02 0xba 0x03 0xb2 0x04 0xbd 0x05 0xf9 0x06 0xb1 0x07 0xfc 0x08 0xf8 0x09 0xb0 0x0a 0xb6 0x0b 0xb5 0x0e>;
		};
	};

	dfi@ff630000 {
		reg = <0x00 0xff630000 0x00 0x4000>;
		compatible = "rockchip,rk3399-dfi";
		rockchip,pmu = <0x87>;
		clocks = <0x08 0x179>;
		clock-names = "pclk_ddr_mon";
		status = "disabled";
		linux,phandle = <0x88>;
		phandle = <0x88>;
	};

	dmc {
		compatible = "rockchip,rk3399-dmc";
		devfreq-events = <0x88>;
		interrupts = <0x00 0x01 0x04 0x00>;
		clocks = <0x08 0xaa>;
		clock-names = "dmc_clk";
		ddr_timing = <0x89>;
		status = "disabled";
		operating-points-v2 = <0x8a>;
	};

	vpu_service@ff650000 {
		compatible = "rockchip,vpu_service";
		rockchip,grf = <0x15>;
		iommus = <0x8b>;
		iommu_enabled = <0x01>;
		reg = <0x00 0xff650000 0x00 0x800>;
		interrupts = <0x00 0x71 0x04 0x00 0x00 0x72 0x04 0x00>;
		interrupt-names = "irq_dec", "irq_enc";
		clocks = <0x08 0xeb 0x08 0x1ea>;
		clock-names = "aclk_vcodec", "hclk_vcodec";
		resets = <0x08 0x53 0x08 0x51>;
		reset-names = "video_h", "video_a";
		power-domains = <0x16 0x1f>;
		dev_mode = <0x00>;
		allocator = <0x01>;
		status = "okay";
	};

	iommu@ff650800 {
		compatible = "rockchip,iommu";
		reg = <0x00 0xff650800 0x00 0x40>;
		interrupts = <0x00 0x73 0x04 0x00>;
		interrupt-names = "vpu_mmu";
		clocks = <0x08 0xeb 0x08 0x1ea>;
		clock-names = "aclk", "hclk";
		power-domains = <0x16 0x1f>;
		#iommu-cells = <0x00>;
		linux,phandle = <0x8b>;
		phandle = <0x8b>;
	};

	rkvdec@ff660000 {
		compatible = "rockchip,rkvdec";
		rockchip,grf = <0x15>;
		iommus = <0x8c>;
		iommu_enabled = <0x01>;
		reg = <0x00 0xff660000 0x00 0x400>;
		interrupts = <0x00 0x74 0x04 0x00>;
		interrupt-names = "irq_dec";
		clocks = <0x08 0xed 0x08 0x1ec 0x08 0x9f 0x08 0x9e>;
		clock-names = "aclk_vcodec", "hclk_vcodec", "clk_cabac", "clk_core";
		resets = <0x08 0x5b 0x08 0x59>;
		reset-names = "video_h", "video_a";
		power-domains = <0x16 0x20>;
		dev_mode = <0x02>;
		allocator = <0x01>;
		status = "okay";
	};

	iommu@ff660480 {
		compatible = "rockchip,iommu";
		reg = <0x00 0xff660480 0x00 0x40 0x00 0xff6604c0 0x00 0x40>;
		interrupts = <0x00 0x75 0x04 0x00>;
		interrupt-names = "vdec_mmu";
		clocks = <0x08 0xed 0x08 0x1ec>;
		clock-names = "aclk", "hclk";
		power-domains = <0x16 0x20>;
		#iommu-cells = <0x00>;
		linux,phandle = <0x8c>;
		phandle = <0x8c>;
	};

	iep@ff670000 {
		compatible = "rockchip,iep";
		iommu_enabled = <0x01>;
		iommus = <0x8d>;
		reg = <0x00 0xff670000 0x00 0x800>;
		interrupts = <0x00 0x2a 0x04 0x00>;
		clocks = <0x08 0xe1 0x08 0x1dd>;
		clock-names = "aclk_iep", "hclk_iep";
		power-domains = <0x16 0x22>;
		allocator = <0x01>;
		version = <0x02>;
		status = "okay";
	};

	iommu@ff670800 {
		compatible = "rockchip,iommu";
		reg = <0x00 0xff670800 0x00 0x40>;
		interrupts = <0x00 0x2a 0x04 0x00>;
		interrupt-names = "iep_mmu";
		#iommu-cells = <0x00>;
		status = "okay";
		linux,phandle = <0x8d>;
		phandle = <0x8d>;
	};

	rga@ff680000 {
		compatible = "rockchip,rga2";
		reg = <0x00 0xff680000 0x00 0x1000>;
		interrupts = <0x00 0x37 0x04 0x00>;
		interrupt-names = "rga";
		clocks = <0x08 0xdc 0x08 0x1e5 0x08 0x6d>;
		clock-names = "aclk_rga", "hclk_rga", "clk_rga";
		resets = <0x08 0x6a 0x08 0x67 0x08 0x69>;
		reset-names = "core", "axi", "ahb";
		power-domains = <0x16 0x21>;
		status = "okay";
		dev_mode = <0x01>;
		dma-coherent;
	};

	efuse@ff690000 {
		compatible = "rockchip,rk3399-efuse";
		reg = <0x00 0xff690000 0x00 0x80>;
		#address-cells = <0x01>;
		#size-cells = <0x01>;
		clocks = <0x08 0x17d>;
		clock-names = "pclk_efuse";

		id {
			reg = <0x07 0x10>;
			linux,phandle = <0xbe>;
			phandle = <0xbe>;
		};

		cpul-leakage {
			reg = <0x1a 0x01>;
		};

		cpub-leakage {
			reg = <0x17 0x01>;
		};

		gpu-leakage {
			reg = <0x18 0x01>;
		};

		center-leakage {
			reg = <0x19 0x01>;
		};

		logic-leakage {
			reg = <0x1b 0x01>;
		};

		wafer-info {
			reg = <0x1c 0x01>;
		};
	};

	pmu-clock-controller@ff750000 {
		compatible = "rockchip,rk3399-pmucru";
		reg = <0x00 0xff750000 0x00 0x1000>;
		#clock-cells = <0x01>;
		#reset-cells = <0x01>;
		assigned-clocks = <0x30 0x01>;
		assigned-clock-rates = <0x284af100>;
		linux,phandle = <0x30>;
		phandle = <0x30>;
	};

	clock-controller@ff760000 {
		compatible = "rockchip,rk3399-cru";
		reg = <0x00 0xff760000 0x00 0x1000>;
		#clock-cells = <0x01>;
		#reset-cells = <0x01>;
		assigned-clocks = <0x08 0xc0 0x08 0xc2 0x08 0x1c2 0x08 0x4c 0x08 0xf0 0x08 0xcd 0x08 0x1cd 0x08 0x9f 0x08 0x9e 0x08 0xf4 0x08 0xbe 0x08 0xc9 0x08 0x186 0x08 0xd5 0x08 0x88 0x08 0x87 0x08 0x08 0x08 0x09 0x08 0x06 0x08 0xd0 0x08 0x05 0x08 0xc0 0x08 0x1c0 0x08 0x140 0x08 0xc2 0x08 0x1c1 0x08 0x142 0x08 0x1c2 0x08 0x143 0x08 0x41 0x08 0x42 0x08 0x43 0x08 0x44 0x08 0x45 0x08 0x46 0x08 0x47 0x08 0x48 0x08 0x49 0x08 0x4a 0x08 0x4b 0x08 0xfa 0x08 0xe5 0x08 0xe6 0x08 0x6b 0x08 0x6c 0x08 0x16a 0x08 0xde 0x08 0xe3 0x08 0x1cd 0x08 0x85 0x08 0x86 0x08 0x4e 0x08 0xf0 0x08 0xcd 0x08 0xe1 0x08 0xdc 0x08 0x6d 0x08 0xed 0x08 0xeb 0x08 0x178 0x08 0xd5 0x08 0x9f 0x08 0x9e 0x08 0xf4 0x08 0xbe 0x08 0xc9 0x08 0x186 0x08 0x88 0x08 0x87 0x08 0xd9 0x08 0x1d9 0x08 0xdb 0x08 0x1db>;
		assigned-clock-rates = <0x47868c0 0x2faf080 0x2faf080 0x2faf080 0x2faf080 0x5f5e100 0x2faf080 0x8f0d180 0x8f0d180 0x8f0d180 0x2faf080 0x8f0d180 0x2faf080 0x5f5e100 0x47868c0 0x47868c0 0x30a32c00 0x30a32c00 0x23c34600 0xbebc200 0x2faf0800 0x8f0d180 0x47868c0 0x23c3460 0x5f5e100 0x5f5e100 0x2faf080 0x5f5e100 0x2faf080 0x5f5e100 0x5f5e100 0x5f5e100 0x5f5e100 0x5f5e100 0x5f5e100 0x2faf080 0x2faf080 0x2faf080 0x2faf080 0x2faf080 0xbebc200 0x17d78400 0x17d78400 0x5f5e100 0x5f5e100 0x5f5e100 0x17d78400 0x17d78400 0xbebc200 0x5f5e100 0xbebc200 0xbebc200 0x5f5e100 0x17d78400 0x17d78400 0x17d78400 0x17d78400 0x11e1a300 0x17d78400 0xbebc200 0x17d78400 0x11e1a300 0x11e1a300 0x11e1a300 0x11e1a300 0x11e1a300 0x5f5e100 0x8f0d180 0x8f0d180 0x17d78400 0x5f5e100 0x17d78400 0x5f5e100>;
		linux,phandle = <0x08>;
		phandle = <0x08>;
	};

	syscon@ff770000 {
		compatible = "rockchip,rk3399-grf", "syscon", "simple-mfd";
		reg = <0x00 0xff770000 0x00 0x10000>;
		#address-cells = <0x01>;
		#size-cells = <0x01>;
		linux,phandle = <0x15>;
		phandle = <0x15>;

		io-domains {
			compatible = "rockchip,rk3399-io-voltage-domain";
			status = "okay";
			bt656-supply = <0x8e>;
			audio-supply = <0x8e>;
			sdmmc-supply = <0x20>;
			gpio1830-supply = <0x8f>;
		};

		phy@f780 {
			compatible = "rockchip,rk3399-emmc-phy";
			reg = <0xf780 0x24>;
			clocks = <0x90>;
			clock-names = "emmcclk";
			#phy-cells = <0x00>;
			status = "okay";
			linux,phandle = <0x25>;
			phandle = <0x25>;
		};

		usb2-phy@e450 {
			compatible = "rockchip,rk3399-usb2phy";
			reg = <0xe450 0x10>;
			clocks = <0x08 0x7b>;
			clock-names = "phyclk";
			#clock-cells = <0x00>;
			clock-output-names = "clk_usbphy0_480m";
			status = "okay";
			linux,phandle = <0x28>;
			phandle = <0x28>;

			otg-port {
				#phy-cells = <0x00>;
				interrupts = <0x00 0x67 0x04 0x00 0x00 0x68 0x04 0x00 0x00 0x6a 0x04 0x00>;
				interrupt-names = "otg-bvalid", "otg-id", "linestate";
				status = "okay";
				linux,phandle = <0x29>;
				phandle = <0x29>;
			};

			host-port {
				#phy-cells = <0x00>;
				interrupts = <0x00 0x1b 0x04 0x00>;
				interrupt-names = "linestate";
				status = "okay";
				phy-supply = <0x91>;
				linux,phandle = <0x26>;
				phandle = <0x26>;
			};
		};

		usb2-phy@e460 {
			compatible = "rockchip,rk3399-usb2phy";
			reg = <0xe460 0x10>;
			clocks = <0x08 0x7c>;
			clock-names = "phyclk";
			#clock-cells = <0x00>;
			clock-output-names = "clk_usbphy1_480m";
			status = "okay";

			otg-port {
				#phy-cells = <0x00>;
				interrupts = <0x00 0x6c 0x04 0x00 0x00 0x6d 0x04 0x00 0x00 0x6f 0x04 0x00>;
				interrupt-names = "otg-bvalid", "otg-id", "linestate";
				status = "okay";
				linux,phandle = <0x2a>;
				phandle = <0x2a>;
			};

			host-port {
				#phy-cells = <0x00>;
				interrupts = <0x00 0x1f 0x04 0x00>;
				interrupt-names = "linestate";
				status = "okay";
				phy-supply = <0x91>;
				linux,phandle = <0x27>;
				phandle = <0x27>;
			};
		};

		pvtm {
			compatible = "rockchip,rk3399-pvtm";
			clocks = <0x08 0x73 0x08 0x74 0x08 0x75 0x08 0x76>;
			clock-names = "core_l", "core_b", "gpu", "ddr";
			status = "okay";
		};
	};

	phy@ff7c0000 {
		compatible = "rockchip,rk3399-typec-phy";
		reg = <0x00 0xff7c0000 0x00 0x40000>;
		rockchip,grf = <0x15>;
		#phy-cells = <0x01>;
		clocks = <0x08 0x7e 0x08 0x7d>;
		clock-names = "tcpdcore", "tcpdphy-ref";
		assigned-clocks = <0x08 0x7e>;
		assigned-clock-rates = <0x2faf080>;
		power-domains = <0x16 0x08>;
		resets = <0x08 0x95 0x08 0x94 0x08 0x14c>;
		reset-names = "uphy", "uphy-pipe", "uphy-tcphy";
		rockchip,typec-conn-dir = <0xe580 0x00 0x10>;
		rockchip,usb3tousb2-en = <0xe580 0x03 0x13>;
		rockchip,usb3-host-disable = <0x2434 0x00 0x10>;
		rockchip,usb3-host-port = <0x2434 0x0c 0x1c>;
		rockchip,external-psm = <0xe588 0x0e 0x1e>;
		rockchip,pipe-status = <0xe5c0 0x00 0x00>;
		rockchip,uphy-dp-sel = <0x6268 0x13 0x13>;
		status = "disabled";

		dp-port {
			#phy-cells = <0x00>;
			linux,phandle = <0x2c>;
			phandle = <0x2c>;
		};

		usb3-port {
			#phy-cells = <0x00>;
		};
	};

	phy@ff800000 {
		compatible = "rockchip,rk3399-typec-phy";
		reg = <0x00 0xff800000 0x00 0x40000>;
		rockchip,grf = <0x15>;
		#phy-cells = <0x01>;
		clocks = <0x08 0x80 0x08 0x7f>;
		clock-names = "tcpdcore", "tcpdphy-ref";
		assigned-clocks = <0x08 0x80>;
		assigned-clock-rates = <0x2faf080>;
		power-domains = <0x16 0x09>;
		resets = <0x08 0x9d 0x08 0x9c 0x08 0x14d>;
		reset-names = "uphy", "uphy-pipe", "uphy-tcphy";
		rockchip,typec-conn-dir = <0xe58c 0x00 0x10>;
		rockchip,usb3tousb2-en = <0xe58c 0x03 0x13>;
		rockchip,usb3-host-disable = <0x2444 0x00 0x10>;
		rockchip,usb3-host-port = <0x2444 0x0c 0x1c>;
		rockchip,external-psm = <0xe594 0x0e 0x1e>;
		rockchip,pipe-status = <0xe5c0 0x10 0x10>;
		rockchip,uphy-dp-sel = <0x6268 0x03 0x13>;
		status = "okay";

		dp-port {
			#phy-cells = <0x00>;
			linux,phandle = <0x2d>;
			phandle = <0x2d>;
		};

		usb3-port {
			#phy-cells = <0x00>;
			linux,phandle = <0x2b>;
			phandle = <0x2b>;
		};
	};

	watchdog@ff848000 {
		compatible = "snps,dw-wdt";
		reg = <0x00 0xff848000 0x00 0x100>;
		clocks = <0x08 0x17c>;
		interrupts = <0x00 0x78 0x04 0x00>;
	};

	rktimer@ff850000 {
		compatible = "rockchip,rk3399-timer";
		reg = <0x00 0xff850000 0x00 0x1000>;
		interrupts = <0x00 0x51 0x04 0x00>;
		clocks = <0x08 0x168 0x08 0x5a>;
		clock-names = "pclk", "timer";
	};

	spdif@ff870000 {
		compatible = "rockchip,rk3399-spdif";
		reg = <0x00 0xff870000 0x00 0x1000>;
		interrupts = <0x00 0x42 0x04 0x00>;
		dmas = <0x92 0x07>;
		dma-names = "tx";
		clock-names = "mclk", "hclk";
		clocks = <0x08 0x55 0x08 0x1d7>;
		pinctrl-names = "default";
		pinctrl-0 = <0x93>;
		power-domains = <0x16 0x1c>;
		status = "okay";
		assigned-clocks = <0x08 0xb1>;
		assigned-clock-parents = <0x08 0x05>;
		i2c-scl-rising-time-ns = <0x1c2>;
		i2c-scl-falling-time-ns = <0x0f>;
		#sound-dai-cells = <0x00>;
		linux,phandle = <0xd4>;
		phandle = <0xd4>;
	};

	i2s@ff880000 {
		compatible = "rockchip,rk3399-i2s", "rockchip,rk3066-i2s";
		reg = <0x00 0xff880000 0x00 0x1000>;
		rockchip,grf = <0x15>;
		interrupts = <0x00 0x27 0x04 0x00>;
		dmas = <0x92 0x00 0x92 0x01>;
		dma-names = "tx", "rx";
		clock-names = "i2s_clk", "i2s_hclk";
		clocks = <0x08 0x56 0x08 0x1d4>;
		pinctrl-names = "default";
		pinctrl-0 = <0x94>;
		power-domains = <0x16 0x1c>;
		status = "disabled";
		assigned-clocks = <0x08 0xae>;
		assigned-clock-parents = <0x08 0x05>;
		rockchip,i2s-broken-burst-len;
		rockchip,playback-channels = <0x08>;
		rockchip,capture-channels = <0x08>;
		#sound-dai-cells = <0x00>;
	};

	i2s@ff890000 {
		compatible = "rockchip,rk3399-i2s", "rockchip,rk3066-i2s";
		reg = <0x00 0xff890000 0x00 0x1000>;
		interrupts = <0x00 0x28 0x04 0x00>;
		dmas = <0x92 0x02 0x92 0x03>;
		dma-names = "tx", "rx";
		clock-names = "i2s_clk", "i2s_hclk";
		clocks = <0x08 0x57 0x08 0x1d5>;
		pinctrl-names = "default";
		pinctrl-0 = <0x95>;
		power-domains = <0x16 0x1c>;
		status = "okay";
		assigned-clocks = <0x08 0xaf 0x08 0x109>;
		assigned-clock-parents = <0x08 0x05 0x08 0x57>;
		rockchip,i2s-broken-burst-len;
		rockchip,playback-channels = <0x02>;
		rockchip,capture-channels = <0x02>;
		#sound-dai-cells = <0x00>;
		linux,phandle = <0xd2>;
		phandle = <0xd2>;
	};

	i2s@ff8a0000 {
		compatible = "rockchip,rk3399-i2s", "rockchip,rk3066-i2s";
		reg = <0x00 0xff8a0000 0x00 0x1000>;
		interrupts = <0x00 0x29 0x04 0x00>;
		dmas = <0x92 0x04>;
		dma-names = "tx";
		clock-names = "i2s_clk", "i2s_hclk";
		clocks = <0x08 0x58 0x08 0x1d6>;
		power-domains = <0x16 0x1c>;
		status = "disabled";
		assigned-clocks = <0x08 0xb0>;
		assigned-clock-parents = <0x08 0x05>;
		#sound-dai-cells = <0x00>;
		linux,phandle = <0xc7>;
		phandle = <0xc7>;
	};

	gpu@ff9a0000 {
		compatible = "arm,malit860", "arm,malit86x", "arm,malit8xx", "arm,mali-midgard";
		reg = <0x00 0xff9a0000 0x00 0x10000>;
		interrupts = <0x00 0x13 0x04 0x00 0x00 0x14 0x04 0x00 0x00 0x15 0x04 0x00>;
		interrupt-names = "GPU", "JOB", "MMU";
		clocks = <0x08 0xd0>;
		clock-names = "clk_mali";
		#cooling-cells = <0x02>;
		power-domains = <0x16 0x23>;
		power-off-delay-ms = <0xc8>;
		status = "okay";
		operating-points-v2 = <0x96>;
		mali-supply = <0x97>;
		linux,phandle = <0x5c>;
		phandle = <0x5c>;

		power_model {
			compatible = "arm,mali-simple-power-model";
			voltage = <0x384>;
			frequency = <0x1f4>;
			static-power = <0x12c>;
			dynamic-power = <0x18c>;
			ts = <0x7d00 0x125c 0xffffffb0 0x02>;
			thermal-zone = "gpu-thermal";
		};
	};

	vop@ff8f0000 {
		compatible = "rockchip,rk3399-vop-lit";
		reg = <0x00 0xff8f0000 0x00 0x1ffc 0x00 0xff8f2000 0x00 0x400>;
		interrupts = <0x00 0x77 0x04 0x00>;
		clocks = <0x08 0xdb 0x08 0xb5 0x08 0x1db 0x08 0xb7>;
		clock-names = "aclk_vop", "dclk_vop", "hclk_vop", "dclk_source";
		resets = <0x08 0x113 0x08 0x117 0x08 0x119>;
		reset-names = "axi", "ahb", "dclk";
		power-domains = <0x16 0x12>;
		iommus = <0x98>;
		status = "okay";
		assigned-clocks = <0x08 0xb7>;
		assigned-clock-parents = <0x08 0x07>;

		port {
			#address-cells = <0x01>;
			#size-cells = <0x00>;
			linux,phandle = <0xb1>;
			phandle = <0xb1>;

			endpoint@0 {
				reg = <0x00>;
				remote-endpoint = <0x99>;
				linux,phandle = <0xa9>;
				phandle = <0xa9>;
			};

			endpoint@1 {
				reg = <0x01>;
				remote-endpoint = <0x9a>;
				linux,phandle = <0xaf>;
				phandle = <0xaf>;
			};

			endpoint@2 {
				reg = <0x02>;
				remote-endpoint = <0x9b>;
				linux,phandle = <0xa6>;
				phandle = <0xa6>;
			};

			endpoint@3 {
				reg = <0x03>;
				remote-endpoint = <0x9c>;
				linux,phandle = <0x2f>;
				phandle = <0x2f>;
			};
		};
	};

	voppwm@ff8f01a0 {
		compatible = "rockchip,vop-pwm";
		reg = <0x00 0xff8f01a0 0x00 0x10>;
		#pwm-cells = <0x03>;
		pinctrl-names = "default";
		pinctrl-0 = <0x9d>;
		clocks = <0x08 0x6c>;
		clock-names = "pwm";
		status = "disabled";
	};

	iommu@ff8f3f00 {
		compatible = "rockchip,iommu";
		reg = <0x00 0xff8f3f00 0x00 0x100>;
		interrupts = <0x00 0x77 0x04 0x00>;
		interrupt-names = "vopl_mmu";
		clocks = <0x08 0xdb 0x08 0x1db>;
		clock-names = "aclk", "hclk";
		power-domains = <0x16 0x12>;
		#iommu-cells = <0x00>;
		status = "okay";
		linux,phandle = <0x98>;
		phandle = <0x98>;
	};

	vop@ff900000 {
		compatible = "rockchip,rk3399-vop-big";
		reg = <0x00 0xff900000 0x00 0x1ffc 0x00 0xff902000 0x00 0x1000>;
		interrupts = <0x00 0x76 0x04 0x00>;
		clocks = <0x08 0xd9 0x08 0xb4 0x08 0x1d9 0x08 0xb6>;
		clock-names = "aclk_vop", "dclk_vop", "hclk_vop", "dclk_source";
		resets = <0x08 0x112 0x08 0x116 0x08 0x118>;
		reset-names = "axi", "ahb", "dclk";
		power-domains = <0x16 0x11>;
		iommus = <0x9e>;
		status = "okay";
		assigned-clocks = <0x08 0xb6>;
		assigned-clock-parents = <0x08 0x04>;

		port {
			#address-cells = <0x01>;
			#size-cells = <0x00>;
			linux,phandle = <0xb0>;
			phandle = <0xb0>;

			endpoint@0 {
				reg = <0x00>;
				remote-endpoint = <0x9f>;
				linux,phandle = <0xae>;
				phandle = <0xae>;
			};

			endpoint@1 {
				reg = <0x01>;
				remote-endpoint = <0xa0>;
				linux,phandle = <0xa8>;
				phandle = <0xa8>;
			};

			endpoint@2 {
				reg = <0x02>;
				remote-endpoint = <0xa1>;
				linux,phandle = <0xa5>;
				phandle = <0xa5>;
			};

			endpoint@3 {
				reg = <0x03>;
				remote-endpoint = <0xa2>;
				linux,phandle = <0x2e>;
				phandle = <0x2e>;
			};
		};
	};

	voppwm@ff9001a0 {
		compatible = "rockchip,vop-pwm";
		reg = <0x00 0xff9001a0 0x00 0x10>;
		#pwm-cells = <0x03>;
		pinctrl-names = "default";
		pinctrl-0 = <0xa3>;
		clocks = <0x08 0x6b>;
		clock-names = "pwm";
		status = "disabled";
	};

	iommu@ff903f00 {
		compatible = "rockchip,iommu";
		reg = <0x00 0xff903f00 0x00 0x100>;
		interrupts = <0x00 0x76 0x04 0x00>;
		interrupt-names = "vopb_mmu";
		clocks = <0x08 0xd9 0x08 0x1d9>;
		clock-names = "aclk", "hclk";
		power-domains = <0x16 0x11>;
		#iommu-cells = <0x00>;
		status = "okay";
		linux,phandle = <0x9e>;
		phandle = <0x9e>;
	};

	iommu@ff914000 {
		compatible = "rockchip,iommu";
		reg = <0x00 0xff914000 0x00 0x100 0x00 0xff915000 0x00 0x100>;
		interrupts = <0x00 0x2b 0x04 0x00>;
		interrupt-names = "isp0_mmu";
		#iommu-cells = <0x00>;
		clocks = <0x08 0xe7 0x08 0x1e1>;
		clock-names = "aclk", "hclk";
		power-domains = <0x16 0x13>;
		rk_iommu,disable_reset_quirk;
		status = "okay";
		linux,phandle = <0xc5>;
		phandle = <0xc5>;
	};

	iommu@ff924000 {
		compatible = "rockchip,iommu";
		reg = <0x00 0xff924000 0x00 0x100 0x00 0xff925000 0x00 0x100>;
		interrupts = <0x00 0x2c 0x04 0x00>;
		interrupt-names = "isp1_mmu";
		#iommu-cells = <0x00>;
		clocks = <0x08 0xe8 0x08 0x1e2>;
		clock-names = "aclk", "hclk";
		power-domains = <0x16 0x14>;
		rk_iommu,disable_reset_quirk;
		status = "disabled";
		linux,phandle = <0xc6>;
		phandle = <0xc6>;
	};

	hdmi@ff940000 {
		compatible = "rockchip,rk3399-dw-hdmi";
		reg = <0x00 0xff940000 0x00 0x20000>;
		reg-io-width = <0x04>;
		rockchip,grf = <0x15>;
		pinctrl-names = "default";
		pinctrl-0 = <0xa4>;
		power-domains = <0x16 0x15>;
		interrupts = <0x00 0x17 0x04 0x00>;
		clocks = <0x08 0x174 0x08 0x71 0x08 0x07 0x08 0x16f>;
		clock-names = "iahb", "isfr", "vpll", "grf";
		status = "okay";
		#address-cells = <0x01>;
		#size-cells = <0x00>;
		#sound-dai-cells = <0x00>;
		ddc-i2c-scl-high-time-ns = <0x2599>;
		ddc-i2c-scl-low-time-ns = <0x2710>;
		rockchip,phy-table = <0x46cf710 0x8009 0x04 0x272 0x9d5b340 0x802b 0x04 0x209 0x11b3dc40 0x8039 0x05 0x28d 0x2367b880 0x8039 0x00 0x19d 0x00 0x00 0x00 0x00>;
		linux,phandle = <0xc8>;
		phandle = <0xc8>;

		ports {

			port {
				#address-cells = <0x01>;
				#size-cells = <0x00>;

				endpoint@0 {
					reg = <0x00>;
					remote-endpoint = <0xa5>;
					linux,phandle = <0xa1>;
					phandle = <0xa1>;
				};

				endpoint@1 {
					reg = <0x01>;
					remote-endpoint = <0xa6>;
					status = "okay";
					linux,phandle = <0x9b>;
					phandle = <0x9b>;
				};
			};
		};
	};

	dsi@ff960000 {
		compatible = "rockchip,rk3399-dsi";
		reg = <0x00 0xff960000 0x00 0x8000>;
		interrupts = <0x00 0x2d 0x04 0x00>;
		clocks = <0x08 0x77 0x08 0x170 0x08 0xa3>;
		clock-names = "ref", "pclk", "phy_cfg";
		resets = <0x08 0xfb>;
		reset-names = "pclkrstz";
		power-domains = <0x16 0x0f>;
		rockchip,grf = <0x15>;
		#address-cells = <0x01>;
		#size-cells = <0x00>;
		status = "okay";
		enable-gpios = <0x33 0x03 0x00>;
		reset-gpios = <0xa7 0x02 0x01>;

		ports {
			#address-cells = <0x01>;
			#size-cells = <0x00>;

			port@0 {
				reg = <0x00>;
				#address-cells = <0x01>;
				#size-cells = <0x00>;

				endpoint@0 {
					reg = <0x00>;
					remote-endpoint = <0xa8>;
					linux,phandle = <0xa0>;
					phandle = <0xa0>;
				};

				endpoint@1 {
					reg = <0x01>;
					remote-endpoint = <0xa9>;
					status = "disabled";
					linux,phandle = <0x99>;
					phandle = <0x99>;
				};
			};

			port@1 {
				reg = <0x01>;

				endpoint {
					remote-endpoint = <0xaa>;
					linux,phandle = <0xac>;
					phandle = <0xac>;
				};
			};
		};

		panel@0 {
			compatible = "simple-panel-dsi";
			reg = <0x00>;
			dsi,flags = <0xa03>;
			dsi,format = <0x00>;
			dsi,lanes = <0x04>;
			panel-init-sequence = [29 00 06 14 01 08 00 00 00 29 00 06 3c 01 0c 00 0a 00 29 00 06 64 01 0d 00 00 00 29 00 06 68 01 0d 00 00 00 29 00 06 6c 01 0d 00 00 00 29 00 06 70 01 0d 00 00 00 29 00 06 34 01 1f 00 00 00 29 00 06 10 02 1f 00 00 00 29 00 06 04 01 01 00 00 00 29 00 06 04 02 01 00 00 00 29 00 06 50 04 00 01 f0 03 29 00 06 54 04 14 00 64 00 29 00 06 58 04 80 07 a0 00 29 00 06 5c 04 0a 00 19 00 29 00 06 60 04 38 04 0a 00 29 00 06 64 04 01 00 00 00 29 00 06 a0 04 06 00 00 00 29 00 06 04 05 04 00 00 00 29 00 06 80 04 00 01 02 03 29 00 06 84 04 04 07 05 08 29 00 06 88 04 09 0a 0e 0f 29 00 06 8c 04 0b 0c 0d 10 29 00 06 90 04 16 17 11 12 29 00 06 94 04 13 14 15 1b 29 14 06 98 04 18 19 1a 06 29 78 06 9c 04 33 04 00 00];

			display-timings {
				native-mode = <0xab>;

				timing0 {
					clock-frequency = <0x8f0d180>;
					hactive = <0x780>;
					vactive = <0x438>;
					hback-porch = <0x64>;
					hsync-len = <0x14>;
					hfront-porch = <0xa0>;
					vback-porch = <0x19>;
					vfront-porch = <0x0a>;
					vsync-len = <0x0a>;
					hsync-active = <0x00>;
					vsync-active = <0x00>;
					de-active = <0x00>;
					pixelclk-active = <0x00>;
					linux,phandle = <0xab>;
					phandle = <0xab>;
				};
			};

			port {

				endpoint {
					remote-endpoint = <0xac>;
					linux,phandle = <0xaa>;
					phandle = <0xaa>;
				};
			};
		};
	};

	edp@ff970000 {
		compatible = "rockchip,rk3399-edp";
		reg = <0x00 0xff970000 0x00 0x8000>;
		interrupts = <0x00 0x0a 0x04 0x00>;
		clocks = <0x08 0x16a 0x08 0x16c>;
		clock-names = "dp", "pclk";
		power-domains = <0x16 0x19>;
		resets = <0x08 0x11d>;
		reset-names = "dp";
		rockchip,grf = <0x15>;
		status = "disabled";
		pinctrl-names = "default";
		pinctrl-0 = <0xad>;

		ports {
			#address-cells = <0x01>;
			#size-cells = <0x00>;

			port@0 {
				reg = <0x00>;
				#address-cells = <0x01>;
				#size-cells = <0x00>;

				endpoint@0 {
					reg = <0x00>;
					remote-endpoint = <0xae>;
					linux,phandle = <0x9f>;
					phandle = <0x9f>;
				};

				endpoint@1 {
					reg = <0x01>;
					remote-endpoint = <0xaf>;
					linux,phandle = <0x9a>;
					phandle = <0x9a>;
				};
			};
		};
	};

	display-subsystem {
		compatible = "rockchip,display-subsystem";
		ports = <0xb0 0xb1>;
		clocks = <0x08 0x07 0x08 0x04>;
		clock-names = "hdmi-tmds-pll", "default-vop-pll";
		status = "okay";
		memory-region = <0xb2>;

		route {

			route-hdmi {
				status = "okay";
				logo,uboot = "logo.bmp";
				logo,kernel = "logo_kernel.bmp";
				logo,mode = "center";
				charge_logo,mode = "center";
				connect = <0xa6>;
			};

			route_dsi {
				status = "okay";
				logo,uboot = "logo.bmp";
				logo,kernel = "logo_kernel.bmp";
				logo,mode = "center";
				charge_logo,mode = "center";
				connect = <0xa8>;
			};

			route-edp {
				status = "disabled";
				logo,uboot = "logo.bmp";
				logo,kernel = "logo_kernel.bmp";
				logo,mode = "fullscreen";
				charge_logo,mode = "center";
				connect = <0xae>;
			};
		};
	};

	pinctrl {
		compatible = "rockchip,rk3399-pinctrl";
		rockchip,grf = <0x15>;
		rockchip,pmu = <0x87>;
		#address-cells = <0x02>;
		#size-cells = <0x02>;
		ranges;
		pinctrl-names = "default";
		pinctrl-0 = <0xb3>;

		gpio0@ff720000 {
			compatible = "rockchip,gpio-bank";
			reg = <0x00 0xff720000 0x00 0x100>;
			clocks = <0x30 0x17>;
			interrupts = <0x00 0x0e 0x04 0x00>;
			gpio-controller;
			#gpio-cells = <0x02>;
			interrupt-controller;
			#interrupt-cells = <0x02>;
			linux,phandle = <0xce>;
			phandle = <0xce>;
		};

		gpio1@ff730000 {
			compatible = "rockchip,gpio-bank";
			reg = <0x00 0xff730000 0x00 0x100>;
			clocks = <0x30 0x18>;
			interrupts = <0x00 0x0f 0x04 0x00>;
			gpio-controller;
			#gpio-cells = <0x02>;
			interrupt-controller;
			#interrupt-cells = <0x02>;
			linux,phandle = <0x33>;
			phandle = <0x33>;
		};

		gpio2@ff780000 {
			compatible = "rockchip,gpio-bank";
			reg = <0x00 0xff780000 0x00 0x100>;
			clocks = <0x08 0x150>;
			interrupts = <0x00 0x10 0x04 0x00>;
			gpio-controller;
			#gpio-cells = <0x02>;
			interrupt-controller;
			#interrupt-cells = <0x02>;
			linux,phandle = <0xa7>;
			phandle = <0xa7>;
		};

		gpio3@ff788000 {
			compatible = "rockchip,gpio-bank";
			reg = <0x00 0xff788000 0x00 0x100>;
			clocks = <0x08 0x151>;
			interrupts = <0x00 0x11 0x04 0x00>;
			gpio-controller;
			#gpio-cells = <0x02>;
			interrupt-controller;
			#interrupt-cells = <0x02>;
			linux,phandle = <0x18>;
			phandle = <0x18>;
		};

		gpio4@ff790000 {
			compatible = "rockchip,gpio-bank";
			reg = <0x00 0xff790000 0x00 0x100>;
			clocks = <0x08 0x152>;
			interrupts = <0x00 0x12 0x04 0x00>;
			gpio-controller;
			#gpio-cells = <0x02>;
			interrupt-controller;
			#interrupt-cells = <0x02>;
			linux,phandle = <0xcb>;
			phandle = <0xcb>;
		};

		pcfg-pull-up {
			bias-pull-up;
			linux,phandle = <0xba>;
			phandle = <0xba>;
		};

		pcfg-pull-down {
			bias-pull-down;
			linux,phandle = <0xbd>;
			phandle = <0xbd>;
		};

		pcfg-pull-none {
			bias-disable;
			linux,phandle = <0xb5>;
			phandle = <0xb5>;
		};

		pcfg-pull-up-20ma {
			bias-pull-up;
			drive-strength = <0x14>;
			linux,phandle = <0xb8>;
			phandle = <0xb8>;
		};

		pcfg-pull-none-20ma {
			bias-disable;
			drive-strength = <0x14>;
			linux,phandle = <0xb9>;
			phandle = <0xb9>;
		};

		pcfg-pull-none-18ma {
			bias-disable;
			drive-strength = <0x12>;
			linux,phandle = <0xbc>;
			phandle = <0xbc>;
		};

		pcfg-pull-none-12ma {
			bias-disable;
			drive-strength = <0x0c>;
			linux,phandle = <0xb7>;
			phandle = <0xb7>;
		};

		pcfg-pull-up-8ma {
			bias-pull-up;
			drive-strength = <0x08>;
			linux,phandle = <0xbb>;
			phandle = <0xbb>;
		};

		pcfg-pull-down-4ma {
			bias-pull-down;
			drive-strength = <0x04>;
		};

		pcfg-pull-up-2ma {
			bias-pull-up;
			drive-strength = <0x02>;
		};

		pcfg-pull-down-12ma {
			bias-pull-down;
			drive-strength = <0x0c>;
		};

		pcfg-pull-none-13ma {
			bias-disable;
			drive-strength = <0x0d>;
			linux,phandle = <0xb4>;
			phandle = <0xb4>;
		};

		pcfg-output-high {
			output-high;
		};

		pcfg-output-low {
			output-low;
			linux,phandle = <0xb6>;
			phandle = <0xb6>;
		};

		pcfg-input {
			input-enable;
		};

		gmac {

			rgmii-pins {
				rockchip,pins = <0x03 0x11 0x01 0xb4 0x03 0x0e 0x01 0xb5 0x03 0x0d 0x01 0xb5 0x03 0x0c 0x01 0xb4 0x03 0x0b 0x01 0xb5 0x03 0x09 0x01 0xb5 0x03 0x08 0x01 0xb5 0x03 0x07 0x01 0xb5 0x03 0x06 0x01 0xb5 0x03 0x05 0x01 0xb4 0x03 0x04 0x01 0xb4 0x03 0x03 0x01 0xb5 0x03 0x02 0x01 0xb5 0x03 0x01 0x01 0xb4 0x03 0x00 0x01 0xb4>;
				linux,phandle = <0x1a>;
				phandle = <0x1a>;
			};

			rmii-pins {
				rockchip,pins = <0x03 0x0d 0x01 0xb5 0x03 0x0c 0x01 0xb4 0x03 0x0b 0x01 0xb5 0x03 0x0a 0x01 0xb5 0x03 0x09 0x01 0xb5 0x03 0x08 0x01 0xb5 0x03 0x07 0x01 0xb5 0x03 0x06 0x01 0xb5 0x03 0x05 0x01 0xb4 0x03 0x04 0x01 0xb4>;
			};

			rgmii-sleep-pins {
				rockchip,pins = <0x03 0x0f 0x00 0xb6>;
				linux,phandle = <0x1b>;
				phandle = <0x1b>;
			};
		};

		i2c0 {

			i2c0-xfer {
				rockchip,pins = <0x01 0x0f 0x02 0xb5 0x01 0x10 0x02 0xb5>;
				linux,phandle = <0x31>;
				phandle = <0x31>;
			};
		};

		i2c1 {

			i2c1-xfer {
				rockchip,pins = <0x04 0x02 0x01 0xb5 0x04 0x01 0x01 0xb5>;
				linux,phandle = <0x39>;
				phandle = <0x39>;
			};
		};

		i2c2 {

			i2c2-xfer {
				rockchip,pins = <0x02 0x01 0x02 0xb7 0x02 0x00 0x02 0xb7>;
				linux,phandle = <0x3a>;
				phandle = <0x3a>;
			};
		};

		i2c3 {

			i2c3-xfer {
				rockchip,pins = <0x04 0x11 0x01 0xb5 0x04 0x10 0x01 0xb5>;
				linux,phandle = <0x3b>;
				phandle = <0x3b>;
			};

			i2c3_gpio {
				rockchip,pins = <0x04 0x11 0x00 0xb5 0x04 0x10 0x00 0xb5>;
			};
		};

		i2c4 {

			i2c4-xfer {
				rockchip,pins = <0x01 0x0c 0x01 0xb5 0x01 0x0b 0x01 0xb5>;
				linux,phandle = <0x7d>;
				phandle = <0x7d>;
			};
		};

		i2c5 {

			i2c5-xfer {
				rockchip,pins = <0x03 0x0b 0x02 0xb5 0x03 0x0a 0x02 0xb5>;
				linux,phandle = <0x3c>;
				phandle = <0x3c>;
			};
		};

		i2c6 {

			i2c6-xfer {
				rockchip,pins = <0x02 0x0a 0x02 0xb5 0x02 0x09 0x02 0xb5>;
				linux,phandle = <0x3d>;
				phandle = <0x3d>;
			};
		};

		i2c7 {

			i2c7-xfer {
				rockchip,pins = <0x02 0x08 0x02 0xb5 0x02 0x07 0x02 0xb5>;
				linux,phandle = <0x3e>;
				phandle = <0x3e>;
			};
		};

		i2c8 {

			i2c8-xfer {
				rockchip,pins = <0x01 0x15 0x01 0xb5 0x01 0x14 0x01 0xb5>;
				linux,phandle = <0x7f>;
				phandle = <0x7f>;
			};
		};

		i2s0 {

			i2s0-8ch-bus {
				rockchip,pins = <0x03 0x18 0x01 0xb5 0x03 0x19 0x01 0xb5 0x03 0x1a 0x01 0xb5 0x03 0x1b 0x01 0xb5 0x03 0x1c 0x01 0xb5 0x03 0x1d 0x01 0xb5 0x03 0x1e 0x01 0xb5 0x03 0x1f 0x01 0xb5 0x04 0x00 0x01 0xb5>;
				linux,phandle = <0x94>;
				phandle = <0x94>;
			};
		};

		i2s1 {

			i2s1-2ch-bus {
				rockchip,pins = <0x04 0x03 0x01 0xb5 0x04 0x04 0x01 0xb5 0x04 0x05 0x01 0xb5 0x04 0x06 0x01 0xb5 0x04 0x07 0x01 0xb5 0x04 0x00 0x01 0xb5>;
				linux,phandle = <0x95>;
				phandle = <0x95>;
			};
		};

		sdio0 {

			sdio0-bus1 {
				rockchip,pins = <0x02 0x14 0x01 0xb8>;
			};

			sdio0-bus4 {
				rockchip,pins = <0x02 0x14 0x01 0xb8 0x02 0x15 0x01 0xb8 0x02 0x16 0x01 0xb8 0x02 0x17 0x01 0xb8>;
				linux,phandle = <0x1d>;
				phandle = <0x1d>;
			};

			sdio0-cmd {
				rockchip,pins = <0x02 0x18 0x01 0xb8>;
				linux,phandle = <0x1e>;
				phandle = <0x1e>;
			};

			sdio0-clk {
				rockchip,pins = <0x02 0x19 0x01 0xb9>;
				linux,phandle = <0x1f>;
				phandle = <0x1f>;
			};

			sdio0-cd {
				rockchip,pins = <0x02 0x1a 0x01 0xba>;
			};

			sdio0-pwr {
				rockchip,pins = <0x02 0x1b 0x01 0xba>;
			};

			sdio0-bkpwr {
				rockchip,pins = <0x02 0x1c 0x01 0xba>;
			};

			sdio0-wp {
				rockchip,pins = <0x00 0x03 0x01 0xba>;
			};

			sdio0-int {
				rockchip,pins = <0x00 0x04 0x01 0xba>;
			};
		};

		sdmmc {

			sdmmc-bus1 {
				rockchip,pins = <0x04 0x08 0x01 0xbb>;
			};

			sdmmc-bus4 {
				rockchip,pins = <0x04 0x08 0x01 0xbb 0x04 0x09 0x01 0xbb 0x04 0x0a 0x01 0xbb 0x04 0x0b 0x01 0xbb>;
				linux,phandle = <0x24>;
				phandle = <0x24>;
			};

			sdmmc-clk {
				rockchip,pins = <0x04 0x0c 0x01 0xbc>;
				linux,phandle = <0x21>;
				phandle = <0x21>;
			};

			sdmmc-cmd {
				rockchip,pins = <0x04 0x0d 0x01 0xbb>;
				linux,phandle = <0x22>;
				phandle = <0x22>;
			};

			sdmcc-cd {
				rockchip,pins = <0x00 0x07 0x01 0xba>;
				linux,phandle = <0x23>;
				phandle = <0x23>;
			};

			sdmmc-wp {
				rockchip,pins = <0x00 0x08 0x01 0xba>;
			};
		};

		spdif {

			spdif-bus {
				rockchip,pins = <0x04 0x15 0x01 0xb5>;
			};

			spdif-bus-1 {
				rockchip,pins = <0x03 0x10 0x03 0xb5>;
				linux,phandle = <0x93>;
				phandle = <0x93>;
			};
		};

		spi0 {

			spi0-clk {
				rockchip,pins = <0x03 0x06 0x02 0xba>;
				linux,phandle = <0x46>;
				phandle = <0x46>;
			};

			spi0-cs0 {
				rockchip,pins = <0x03 0x07 0x02 0xba>;
				linux,phandle = <0x49>;
				phandle = <0x49>;
			};

			spi0-cs1 {
				rockchip,pins = <0x03 0x08 0x02 0xba>;
			};

			spi0-tx {
				rockchip,pins = <0x03 0x05 0x02 0xba>;
				linux,phandle = <0x47>;
				phandle = <0x47>;
			};

			spi0-rx {
				rockchip,pins = <0x03 0x04 0x02 0xba>;
				linux,phandle = <0x48>;
				phandle = <0x48>;
			};
		};

		spi1 {

			spi1-clk {
				rockchip,pins = <0x01 0x09 0x02 0xba>;
				linux,phandle = <0x4a>;
				phandle = <0x4a>;
			};

			spi1-cs0 {
				rockchip,pins = <0x01 0x0a 0x02 0xba>;
				linux,phandle = <0x4d>;
				phandle = <0x4d>;
			};

			spi1-rx {
				rockchip,pins = <0x01 0x07 0x02 0xba>;
				linux,phandle = <0x4c>;
				phandle = <0x4c>;
			};

			spi1-tx {
				rockchip,pins = <0x01 0x08 0x02 0xba>;
				linux,phandle = <0x4b>;
				phandle = <0x4b>;
			};
		};

		spi2 {

			spi2-clk {
				rockchip,pins = <0x02 0x0b 0x01 0xba>;
				linux,phandle = <0x4e>;
				phandle = <0x4e>;
			};

			spi2-cs0 {
				rockchip,pins = <0x02 0x0c 0x01 0xba>;
				linux,phandle = <0x51>;
				phandle = <0x51>;
			};

			spi2-rx {
				rockchip,pins = <0x02 0x09 0x01 0xba>;
				linux,phandle = <0x50>;
				phandle = <0x50>;
			};

			spi2-tx {
				rockchip,pins = <0x02 0x0a 0x01 0xba>;
				linux,phandle = <0x4f>;
				phandle = <0x4f>;
			};
		};

		spi3 {

			spi3-clk {
				rockchip,pins = <0x01 0x11 0x01 0xba>;
				linux,phandle = <0x78>;
				phandle = <0x78>;
			};

			spi3-cs0 {
				rockchip,pins = <0x01 0x12 0x01 0xba>;
				linux,phandle = <0x7b>;
				phandle = <0x7b>;
			};

			spi3-rx {
				rockchip,pins = <0x01 0x0f 0x01 0xba>;
				linux,phandle = <0x7a>;
				phandle = <0x7a>;
			};

			spi3-tx {
				rockchip,pins = <0x01 0x10 0x01 0xba>;
				linux,phandle = <0x79>;
				phandle = <0x79>;
			};
		};

		spi4 {

			spi4-clk {
				rockchip,pins = <0x03 0x02 0x02 0xba>;
				linux,phandle = <0x52>;
				phandle = <0x52>;
			};

			spi4-cs0 {
				rockchip,pins = <0x03 0x03 0x02 0xba>;
				linux,phandle = <0x55>;
				phandle = <0x55>;
			};

			spi4-rx {
				rockchip,pins = <0x03 0x00 0x02 0xba>;
				linux,phandle = <0x54>;
				phandle = <0x54>;
			};

			spi4-tx {
				rockchip,pins = <0x03 0x01 0x02 0xba>;
				linux,phandle = <0x53>;
				phandle = <0x53>;
			};
		};

		spi5 {

			spi5-clk {
				rockchip,pins = <0x02 0x16 0x02 0xba>;
				linux,phandle = <0x56>;
				phandle = <0x56>;
			};

			spi5-cs0 {
				rockchip,pins = <0x02 0x17 0x02 0xba>;
				linux,phandle = <0x59>;
				phandle = <0x59>;
			};

			spi5-rx {
				rockchip,pins = <0x02 0x14 0x02 0xba>;
				linux,phandle = <0x58>;
				phandle = <0x58>;
			};

			spi5-tx {
				rockchip,pins = <0x02 0x15 0x02 0xba>;
				linux,phandle = <0x57>;
				phandle = <0x57>;
			};
		};

		tsadc {

			otp-gpio {
				rockchip,pins = <0x01 0x06 0x00 0xb5>;
				linux,phandle = <0x5d>;
				phandle = <0x5d>;
			};

			otp-out {
				rockchip,pins = <0x01 0x06 0x01 0xb5>;
				linux,phandle = <0x5e>;
				phandle = <0x5e>;
			};
		};

		uart0 {

			uart0-xfer {
				rockchip,pins = <0x02 0x10 0x01 0xba 0x02 0x11 0x01 0xb5>;
				linux,phandle = <0x3f>;
				phandle = <0x3f>;
			};

			uart0-cts {
				rockchip,pins = <0x02 0x12 0x01 0xb5>;
				linux,phandle = <0x40>;
				phandle = <0x40>;
			};

			uart0-rts {
				rockchip,pins = <0x02 0x13 0x01 0xb5>;
				linux,phandle = <0xd6>;
				phandle = <0xd6>;
			};
		};

		uart1 {

			uart1-xfer {
				rockchip,pins = <0x03 0x0c 0x02 0xba 0x03 0x0d 0x02 0xb5>;
				linux,phandle = <0x41>;
				phandle = <0x41>;
			};
		};

		uart2a {

			uart2a-xfer {
				rockchip,pins = <0x04 0x08 0x02 0xba 0x04 0x09 0x02 0xb5>;
			};
		};

		uart2b {

			uart2b-xfer {
				rockchip,pins = <0x04 0x10 0x02 0xba 0x04 0x11 0x02 0xb5>;
			};
		};

		uart2c {

			uart2c-xfer {
				rockchip,pins = <0x04 0x13 0x01 0xba 0x04 0x14 0x01 0xb5>;
				linux,phandle = <0x42>;
				phandle = <0x42>;
			};
		};

		uart3 {

			uart3-xfer {
				rockchip,pins = <0x03 0x0e 0x02 0xba 0x03 0x0f 0x02 0xb5>;
				linux,phandle = <0x43>;
				phandle = <0x43>;
			};

			uart3-cts {
				rockchip,pins = <0x03 0x12 0x02 0xb5>;
				linux,phandle = <0x44>;
				phandle = <0x44>;
			};

			uart3-rts {
				rockchip,pins = <0x03 0x13 0x02 0xb5>;
				linux,phandle = <0x45>;
				phandle = <0x45>;
			};
		};

		uart4 {

			uart4-xfer {
				rockchip,pins = <0x01 0x07 0x01 0xba 0x01 0x08 0x01 0xb5>;
				linux,phandle = <0x7c>;
				phandle = <0x7c>;
			};
		};

		uarthdcp {

			uarthdcp-xfer {
				rockchip,pins = <0x04 0x15 0x02 0xba 0x04 0x16 0x02 0xb5>;
			};
		};

		pwm0 {

			pwm0-pin {
				rockchip,pins = <0x04 0x12 0x01 0xb5>;
				linux,phandle = <0x83>;
				phandle = <0x83>;
			};

			vop0-pwm-pin {
				rockchip,pins = <0x04 0x12 0x02 0xb5>;
				linux,phandle = <0xa3>;
				phandle = <0xa3>;
			};
		};

		pwm1 {

			pwm1-pin {
				rockchip,pins = <0x04 0x16 0x01 0xb5>;
				linux,phandle = <0x84>;
				phandle = <0x84>;
			};

			vop1-pwm-pin {
				rockchip,pins = <0x04 0x12 0x03 0xb5>;
				linux,phandle = <0x9d>;
				phandle = <0x9d>;
			};
		};

		pwm2 {

			pwm2-pin {
				rockchip,pins = <0x01 0x13 0x01 0xb5>;
				linux,phandle = <0x85>;
				phandle = <0x85>;
			};
		};

		pwm3a {

			pwm3a-pin {
				rockchip,pins = <0x00 0x06 0x01 0xb5>;
				linux,phandle = <0x86>;
				phandle = <0x86>;
			};
		};

		pwm3b {

			pwm3b-pin {
				rockchip,pins = <0x01 0x0e 0x01 0xb5>;
			};
		};

		edp {

			edp-hpd {
				rockchip,pins = <0x04 0x17 0x02 0xb5>;
				linux,phandle = <0xad>;
				phandle = <0xad>;
			};
		};

		hdmi {

			hdmi-i2c-xfer {
				rockchip,pins = <0x04 0x11 0x03 0xb5 0x04 0x10 0x03 0xb5>;
				linux,phandle = <0xa4>;
				phandle = <0xa4>;
			};

			hdmi-cec {
				rockchip,pins = <0x04 0x17 0x01 0xb5>;
			};
		};

		pcie {

			pci-clkreqn {
				rockchip,pins = <0x02 0x1a 0x02 0xb5>;
			};

			pci-clkreqnb {
				rockchip,pins = <0x04 0x18 0x01 0xb5>;
			};

			pci-clkreqn-cpm {
				rockchip,pins = <0x02 0x1a 0x00 0xb5>;
			};

			pci-clkreqnb-cpm {
				rockchip,pins = <0x04 0x18 0x00 0xb5>;
			};
		};

		isp {

			cif-clkout {
				rockchip,pins = <0x02 0x0b 0x03 0xb5>;
				linux,phandle = <0xc0>;
				phandle = <0xc0>;
			};

			isp-dvp-d0d7 {
				rockchip,pins = <0x02 0x00 0x03 0xb5 0x02 0x01 0x03 0xb5 0x02 0x02 0x03 0xb5 0x02 0x03 0x03 0xb5 0x02 0x04 0x03 0xb5 0x02 0x05 0x03 0xb5 0x02 0x06 0x03 0xb5 0x02 0x07 0x03 0xb5 0x02 0x08 0x03 0xb5 0x02 0x09 0x03 0xb5 0x02 0x0a 0x03 0xb5>;
				linux,phandle = <0xc1>;
				phandle = <0xc1>;
			};

			isp-shutter {
				rockchip,pins = <0x01 0x01 0x01 0xb5 0x01 0x00 0x01 0xb5>;
			};

			isp-flash-trigger {
				rockchip,pins = <0x01 0x03 0x01 0xb5>;
				linux,phandle = <0xc4>;
				phandle = <0xc4>;
			};

			isp-prelight {
				rockchip,pins = <0x01 0x04 0x01 0xb5>;
				linux,phandle = <0xc2>;
				phandle = <0xc2>;
			};

			isp_flash_trigger_as_gpio {
				rockchip,pins = <0x01 0x03 0x00 0xb5>;
				linux,phandle = <0xc3>;
				phandle = <0xc3>;
			};
		};

		pmic {

			pmic-int-l {
				rockchip,pins = <0x01 0x15 0x00 0xba>;
				linux,phandle = <0x36>;
				phandle = <0x36>;
			};

			pmic-dvs2 {
				rockchip,pins = <0x01 0x12 0x00 0xbd>;
			};

			pmic-stby {
				rockchip,pins = <0x01 0x18 0x00 0xba>;
			};

			pmic-hold {
				rockchip,pins = <0x01 0x0d 0x00 0xba>;
			};

			vsel1-gpio {
				rockchip,pins = <0x01 0x12 0x00 0xbd>;
				linux,phandle = <0x32>;
				phandle = <0x32>;
			};

			vsel2-gpio {
				rockchip,pins = <0x01 0x0e 0x00 0xbd>;
				linux,phandle = <0x35>;
				phandle = <0x35>;
			};
		};

		usb2 {

			host-vbus-drv {
				rockchip,pins = <0x00 0x05 0x00 0xb5>;
				linux,phandle = <0xcf>;
				phandle = <0xcf>;
			};
		};

		fusb30x {

			fusb0-int {
				rockchip,pins = <0x01 0x02 0x00 0xba>;
				linux,phandle = <0x7e>;
				phandle = <0x7e>;
			};
		};

		pinctrl_tngpio {
			rockchip,pins = <0x01 0x0c 0x00 0xb5 0x04 0x1a 0x00 0xb5 0x01 0x0d 0x00 0xb5 0x02 0x03 0x00 0xb5 0x00 0x0b 0x00 0xb5 0x04 0x18 0x00 0xb5 0x01 0x00 0x00 0xb5 0x01 0x18 0x00 0xb5 0x01 0x16 0x00 0xb5 0x03 0x10 0x00 0xb5 0x00 0x0d 0x00 0xb5 0x01 0x04 0x00 0xb5 0x00 0x02 0x00 0xb5 0x00 0x05 0x00 0xb5 0x01 0x12 0x00 0xb5 0x01 0x00 0x00 0xb5>;
			linux,phandle = <0xd1>;
			phandle = <0xd1>;
		};

		sdio-pwrseq {

			wifi-enable-h {
				rockchip,pins = <0x00 0x0a 0x00 0xb5>;
				linux,phandle = <0xcd>;
				phandle = <0xcd>;
			};
		};

		wireless-bluetooth {

			uart0-gpios {
				rockchip,pins = <0x02 0x13 0x00 0xb5>;
				linux,phandle = <0xd7>;
				phandle = <0xd7>;
			};
		};

		compat {

			cpt-gpio {
				rockchip,pins = <0x01 0x12 0x00 0xb6>;
				linux,phandle = <0xb3>;
				phandle = <0xb3>;
			};
		};
	};

	rockchip-suspend {
		compatible = "rockchip,pm-rk3399";
		status = "okay";
		rockchip,sleep-debug-en = <0x00>;
		rockchip,virtual-poweroff = <0x00>;
		rockchip,sleep-mode-config = <0xde>;
		rockchip,wakeup-config = <0x804>;
		rockchip,pwm-regulator-config = <0x04>;
		rockchip,power-ctrl = <0x33 0x11 0x00 0x33 0x0e 0x00>;
	};

	chosen {
		bootargs = "earlycon=uart8250,mmio32,0xff1a0000 swiotlb=1";
	};

	cpuinfo {
		compatible = "rockchip,cpuinfo";
		nvmem-cells = <0xbe>;
		nvmem-cell-names = "id";
	};

	ramoops_mem {
		reg = <0x00 0x110000 0x00 0xf0000>;
		reg-names = "ramoops_mem";
		linux,phandle = <0xbf>;
		phandle = <0xbf>;
	};

	ramoops {
		compatible = "ramoops";
		record-size = <0x00 0x20000>;
		console-size = <0x00 0x80000>;
		ftrace-size = <0x00 0x00>;
		pmsg-size = <0x00 0x50000>;
		memory-region = <0xbf>;
	};

	fiq-debugger {
		compatible = "rockchip,fiq-debugger";
		rockchip,serial-id = <0x02>;
		rockchip,signal-irq = <0xb6>;
		rockchip,wake-irq = <0x00>;
		rockchip,irq-mode-enable = <0x01>;
		rockchip,baudrate = <0x16e360>;
		pinctrl-names = "default";
		pinctrl-0 = <0x42>;
	};

	reserved-memory {
		#address-cells = <0x02>;
		#size-cells = <0x02>;
		ranges;

		drm-logo@00000000 {
			compatible = "rockchip,drm-logo";
			reg = <0x00 0x00 0x00 0x00>;
			linux,phandle = <0xb2>;
			phandle = <0xb2>;
		};

		stb-devinfo@00000000 {
			compatible = "rockchip,stb-devinfo";
			reg = <0x00 0x00 0x00 0x00>;
		};
	};

	isp@ff910000 {
		compatible = "rockchip,rk3399-isp", "rockchip,isp";
		reg = <0x00 0xff910000 0x00 0x4000>;
		interrupts = <0x00 0x2b 0x04 0x00>;
		clocks = <0x08 0x89 0x08 0x89 0x08 0xa4 0x08 0x77 0x08 0xe7 0x08 0xe9 0x08 0x1e1 0x08 0x1e3 0x08 0x6e 0x08 0xa5>;
		clock-names = "clk_cif_out", "clk_cif_pll", "pclk_dphytxrx", "pclk_dphy_ref", "aclk_isp0_noc", "aclk_isp0_wrapper", "hclk_isp0_noc", "hclk_isp0_wrapper", "clk_isp0", "pclk_dphyrx";
		pinctrl-names = "cif_clkout", "isp_dvp8bit0", "isp_mipi_fl", "isp_mipi_fl_prefl", "isp_flash_as_gpio", "isp_flash_as_trigger_out";
		pinctrl-0 = <0xc0>;
		pinctrl-1 = <0xc1>;
		pinctrl-2 = <0xc0>;
		pinctrl-3 = <0xc2>;
		pinctrl-4 = <0xc3>;
		pinctrl-5 = <0xc4>;
		rockchip,isp,mipiphy = <0x02>;
		rockchip,isp,cifphy = <0x01>;
		rockchip,isp,dsiphy,reg = <0xff968000 0x8000>;
		rockchip,grf = <0x15>;
		rockchip,cru = <0x08>;
		rockchip,gpios = <0xa7 0x0c 0x00>;
		rockchip,isp,iommu-enable = <0x01>;
		power-domains = <0x16 0x13>;
		iommus = <0xc5>;
		status = "okay";
	};

	isp@ff920000 {
		compatible = "rockchip,rk3399-isp", "rockchip,isp";
		reg = <0x00 0xff920000 0x00 0x4000>;
		interrupts = <0x00 0x2c 0x04 0x00>;
		clocks = <0x08 0xe8 0x08 0xea 0x08 0x1e2 0x08 0x1e4 0x08 0x6f 0x08 0x89 0x08 0x89 0x08 0xa4 0x08 0x77 0x08 0x17b 0x08 0xa5 0x08 0x171 0x08 0x78>;
		clock-names = "aclk_isp1_noc", "aclk_isp1_wrapper", "hclk_isp1_noc", "hclk_isp1_wrapper", "clk_isp1", "clk_cif_out", "clk_cif_pll", "pclk_dphytxrx", "pclk_dphy_ref", "pclk_isp1", "pclk_dphyrx", "pclk_mipi_dsi", "mipi_dphy_cfg";
		pinctrl-names = "cif_clkout", "isp_dvp8bit0", "isp_mipi_fl", "isp_mipi_fl_prefl", "isp_flash_as_gpio", "isp_flash_as_trigger_out";
		pinctrl-0 = <0xc0>;
		pinctrl-1 = <0xc1>;
		pinctrl-2 = <0xc0>;
		pinctrl-3 = <0xc2>;
		pinctrl-4 = <0xc3>;
		pinctrl-5 = <0xc4>;
		rockchip,isp,mipiphy = <0x02>;
		rockchip,isp,cifphy = <0x01>;
		rockchip,isp,dsiphy,reg = <0xff968000 0x8000>;
		rockchip,grf = <0x15>;
		rockchip,cru = <0x08>;
		rockchip,gpios = <0xa7 0x0c 0x00>;
		rockchip,isp,iommu-enable = <0x01>;
		power-domains = <0x16 0x14>;
		iommus = <0xc6>;
		status = "disabled";
	};

	uboot-charge {
		compatible = "rockchip,uboot-charge";
		rockchip,uboot-charge-on = <0x01>;
		rockchip,android-charge-on = <0x00>;
	};

	hdmi-dp-sound {
		status = "disabled";
		compatible = "rockchip,rk3399-hdmi-dp";
		rockchip,cpu = <0xc7>;
		rockchip,codec = <0xc8 0xc9>;
	};

	energy-costs {

		rk3399-core-cost0 {
			busy-cost-data = <0x6c 0x2e 0x9f 0x43 0xd8 0x5a 0x10b 0x78 0x13e 0x99 0x177 0xc6 0x191 0xde>;
			idle-cost-data = <0x06 0x06 0x00 0x00>;
			linux,phandle = <0x0c>;
			phandle = <0x0c>;
		};

		rk3399-core-cost1 {
			busy-cost-data = <0xd2 0x81 0x134 0xb8 0x1a3 0xf6 0x206 0x14f 0x269 0x1ac 0x2d8 0x23d 0x33b 0x2d4 0x39d 0x384 0x400 0x454>;
			idle-cost-data = <0x0f 0x0f 0x00 0x00>;
			linux,phandle = <0x10>;
			phandle = <0x10>;
		};

		rk3399-cluster-cost0 {
			busy-cost-data = <0x6c 0x2e 0x9f 0x43 0xd8 0x5a 0x10b 0x78 0x13e 0x99 0x177 0xc6 0x191 0xde>;
			idle-cost-data = <0x38 0x38 0x38 0x38>;
			linux,phandle = <0x0d>;
			phandle = <0x0d>;
		};

		rk3399-cluster-cost1 {
			busy-cost-data = <0xd2 0x81 0x134 0xb8 0x1a3 0xf6 0x206 0x14f 0x269 0x1ac 0x2d8 0x23d 0x33b 0x2d4 0x39d 0x384 0x400 0x454>;
			idle-cost-data = <0x41 0x41 0x41 0x41>;
			linux,phandle = <0x11>;
			phandle = <0x11>;
		};
	};

	opp-table0 {
		compatible = "operating-points-v2";
		opp-shared;
		linux,phandle = <0x0b>;
		phandle = <0x0b>;

		opp-408000000 {
			opp-hz = <0x00 0x18519600>;
			opp-microvolt = "", "\f5";
			clock-latency-ns = <0x9c40>;
		};

		opp-600000000 {
			opp-hz = <0x00 0x23c34600>;
			opp-microvolt = "", "\f5";
			clock-latency-ns = <0x9c40>;
		};

		opp-816000000 {
			opp-hz = <0x00 0x30a32c00>;
			opp-microvolt = <0xcf850>;
			clock-latency-ns = <0x9c40>;
			opp-suspend;
		};

		opp-1008000000 {
			opp-hz = <0x00 0x3c14dc00>;
			opp-microvolt = <0xe1d48>;
			clock-latency-ns = <0x9c40>;
		};

		opp-1200000000 {
			opp-hz = <0x00 0x47868c00>;
			opp-microvolt = <0xf4240>;
			clock-latency-ns = <0x9c40>;
		};

		opp-1416000000 {
			opp-hz = <0x00 0x54667200>;
			opp-microvolt = <0x112a88>;
			clock-latency-ns = <0x9c40>;
		};
	};

	opp-table1 {
		compatible = "operating-points-v2";
		opp-shared;
		linux,phandle = <0x0f>;
		phandle = <0x0f>;

		opp-408000000 {
			opp-hz = <0x00 0x18519600>;
			opp-microvolt = "", "\f5";
			clock-latency-ns = <0x9c40>;
		};

		opp-600000000 {
			opp-hz = <0x00 0x23c34600>;
			opp-microvolt = "", "\f5";
			clock-latency-ns = <0x9c40>;
		};

		opp-816000000 {
			opp-hz = <0x00 0x30a32c00>;
			opp-microvolt = <0xc96a8>;
			clock-latency-ns = <0x9c40>;
			opp-suspend;
		};

		opp-1008000000 {
			opp-hz = <0x00 0x3c14dc00>;
			opp-microvolt = <0xd59f8>;
			clock-latency-ns = <0x9c40>;
		};

		opp-1200000000 {
			opp-hz = <0x00 0x47868c00>;
			opp-microvolt = <0xe7ef0>;
			clock-latency-ns = <0x9c40>;
		};

		opp-1416000000 {
			opp-hz = <0x00 0x54667200>;
			opp-microvolt = <0xfa3e8>;
			clock-latency-ns = <0x9c40>;
		};

		opp-1608000000 {
			opp-hz = <0x00 0x5fd82200>;
			opp-microvolt = <0x10c8e0>;
			clock-latency-ns = <0x9c40>;
		};

		opp-1800000000 {
			opp-hz = <0x00 0x6b49d200>;
			opp-microvolt = <0x124f80>;
			clock-latency-ns = <0x9c40>;
		};
	};

	opp-table2 {
		compatible = "operating-points-v2";
		linux,phandle = <0x96>;
		phandle = <0x96>;

		opp-200000000 {
			opp-hz = <0x00 0xbebc200>;
			opp-microvolt = "", "\f5";
		};

		opp-297000000 {
			opp-hz = <0x00 0x11b3dc40>;
			opp-microvolt = "", "\f5";
		};

		opp-400000000 {
			opp-hz = <0x00 0x17d78400>;
			opp-microvolt = <0xc96a8>;
		};

		opp-500000000 {
			opp-hz = <0x00 0x1dcd6500>;
			opp-microvolt = <0xd59f8>;
		};

		opp-600000000 {
			opp-hz = <0x00 0x23c34600>;
			opp-microvolt = <0xe1d48>;
		};

		opp-800000000 {
			opp-hz = <0x00 0x2faf0800>;
			opp-microvolt = <0x10c8e0>;
		};
	};

	opp-table3 {
		compatible = "operating-points-v2";
		linux,phandle = <0x8a>;
		phandle = <0x8a>;

		opp-200000000 {
			opp-hz = <0x00 0xbebc200>;
			opp-microvolt = <0xc96a8>;
		};

		opp-300000000 {
			opp-hz = <0x00 0x11e1a300>;
			opp-microvolt = <0xcf850>;
		};

		opp-400000000 {
			opp-hz = <0x00 0x17d78400>;
			opp-microvolt = <0xcf850>;
		};

		opp-594000000 {
			opp-hz = <0x00 0x2367b880>;
			opp-microvolt = <0xdbba0>;
		};

		opp-800000000 {
			opp-hz = <0x00 0x2faf0800>;
			opp-microvolt = <0xdbba0>;
		};
	};

	backlight {
		status = "okay";
		compatible = "pwm-backlight";
		pwms = <0xca 0x00 0x61a8 0x00>;
		brightness-levels = <0xff 0xfe 0xfd 0xfc 0xfb 0xfa 0xf9 0xf8 0xf7 0xf6 0xf5 0xf4 0xf3 0xf2 0xf1 0xf0 0xef 0xee 0xed 0xec 0xeb 0xea 0xe9 0xe8 0xe7 0xe6 0xe5 0xe4 0xe3 0xe2 0xe1 0xe0 0xdf 0xde 0xdd 0xdc 0xdb 0xda 0xd9 0xd8 0xd7 0xd6 0xd5 0xd4 0xd3 0xd2 0xd1 0xd0 0xcf 0xce 0xcd 0xcc 0xcb 0xca 0xc9 0xc8 0xc7 0xc6 0xc5 0xc4 0xc3 0xc2 0xc1 0xc0 0xbf 0xbe 0xbd 0xbc 0xbb 0xba 0xb9 0xb8 0xb7 0xb6 0xb5 0xb4 0xb3 0xb2 0xb1 0xb0 0xaf 0xae 0xad 0xac 0xab 0xaa 0xa9 0xa8 0xa7 0xa6 0xa5 0xa4 0xa3 0xa2 0xa1 0xa0 0x9f 0x9e 0x9d 0x9c 0x9b 0x9a 0x99 0x98 0x97 0x96 0x95 0x94 0x93 0x92 0x91 0x90 0x8f 0x8e 0x8d 0x8c 0x8b 0x8a 0x89 0x88 0x87 0x86 0x85 0x84 0x83 0x82 0x81 0x80 0x7f 0x7e 0x7d 0x7c 0x7b 0x7a 0x79 0x78 0x77 0x76 0x75 0x74 0x73 0x72 0x71 0x70 0x6f 0x6e 0x6d 0x6c 0x6b 0x6a 0x69 0x68 0x67 0x66 0x65 0x64 0x63 0x62 0x61 0x60 0x5f 0x5e 0x5d 0x5c 0x5b 0x5a 0x59 0x58 0x57 0x56 0x55 0x54 0x53 0x52 0x51 0x50 0x4f 0x4e 0x4d 0x4c 0x4b 0x4a 0x49 0x48 0x47 0x46 0x45 0x44 0x43 0x42 0x41 0x40 0x3f 0x3e 0x3d 0x3c 0x3b 0x3a 0x39 0x38 0x37 0x36 0x35 0x34 0x33 0x32 0x31 0x30 0x2f 0x2e 0x2d 0x2c 0x2b 0x2a 0x29 0x28 0x27 0x26 0x25 0x24 0x23 0x22 0x21 0x20 0x1f 0x1e 0x1d 0x1c 0x1b 0x1a 0x19 0x18 0x17 0x16 0x15 0x14 0x13 0x12 0x11 0x10 0x0f 0x0e 0x0d 0x0c 0x0b 0x0a 0x09 0x08 0x07 0x06 0x05 0x04 0x03 0x02 0x01 0x00>;
		default-brightness-level = <0xff>;
		enable-gpios = <0xcb 0x19 0x00>;
	};

	external-gmac-clock {
		compatible = "fixed-clock";
		clock-frequency = <0x7735940>;
		clock-output-names = "clkin_gmac";
		#clock-cells = <0x00>;
		linux,phandle = <0x19>;
		phandle = <0x19>;
	};

	dw-hdmi-audio {
		status = "disabled";
		compatible = "rockchip,dw-hdmi-audio";
		#sound-dai-cells = <0x00>;
	};

	hdmi-sound {
		status = "disabled";
		compatible = "simple-audio-card";
		simple-audio-card,format = "i2s";
		simple-audio-card,mclk-fs = <0x100>;
		simple-audio-card,name = "rockchip,hdmi";

		simple-audio-card,cpu {
			sound-dai = <0xc7>;
		};

		simple-audio-card,codec {
			sound-dai = <0xc8>;
		};
	};

	sdio-pwrseq {
		compatible = "mmc-pwrseq-simple";
		clocks = <0xcc 0x01>;
		clock-names = "ext_clock";
		pinctrl-names = "default";
		pinctrl-0 = <0xcd>;
		reset-gpios = <0xce 0x0a 0x01>;
		linux,phandle = <0x1c>;
		phandle = <0x1c>;
	};

	vcc3v3-sys {
		compatible = "regulator-fixed";
		regulator-name = "vcc3v3_sys";
		regulator-min-microvolt = <0x325aa0>;
		regulator-max-microvolt = <0x325aa0>;
		regulator-always-on;
		vin-supply = <0x34>;
		linux,phandle = <0x37>;
		phandle = <0x37>;
	};

	vcc5v0-host-regulator {
		compatible = "regulator-fixed";
		enable-active-high;
		gpio = <0xce 0x05 0x00>;
		pinctrl-names = "default";
		pinctrl-0 = <0xcf>;
		regulator-name = "vcc5v0_host";
		regulator-always-on;
		linux,phandle = <0x91>;
		phandle = <0x91>;
	};

	vcc5v0-sys {
		compatible = "regulator-fixed";
		regulator-name = "vcc5v0_sys";
		regulator-always-on;
		regulator-boot-on;
		regulator-min-microvolt = <0x4c4b40>;
		regulator-max-microvolt = <0x4c4b40>;
	};

	vcc1v8-s0 {
		compatible = "regulator-fixed";
		regulator-name = "vcc1v8_s0";
		regulator-min-microvolt = <0x1b7740>;
		regulator-max-microvolt = <0x1b7740>;
		regulator-always-on;
		linux,phandle = <0x8e>;
		phandle = <0x8e>;
	};

	vcc-sys {
		compatible = "regulator-fixed";
		regulator-name = "vcc_sys";
		regulator-min-microvolt = <0x4c4b40>;
		regulator-max-microvolt = <0x4c4b40>;
		regulator-always-on;
		linux,phandle = <0x34>;
		phandle = <0x34>;
	};

	vcc-phy-regulator {
		compatible = "regulator-fixed";
		regulator-name = "vcc_phy";
		regulator-always-on;
		regulator-boot-on;
		linux,phandle = <0x17>;
		phandle = <0x17>;
	};

	vdd-log {
		compatible = "pwm-regulator";
		pwms = <0xd0 0x00 0x61a8 0x01>;
		regulator-name = "vdd_log";
		regulator-min-microvolt = "", "\f5";
		regulator-max-microvolt = <0x155cc0>;
		regulator-always-on;
		regulator-boot-on;
		rockchip,pwm_id = <0x02>;
		rockchip,pwm_voltage = <0x100590>;
		vin-supply = <0x34>;
	};

	tn_gpio {
		compatible = "tn_gpio";
		pinctrl-names = "default";
		pinctrl-0 = <0xd1>;
		status = "okay";
	};

	rt5640-sound {
		compatible = "simple-audio-card";
		simple-audio-card,format = "i2s";
		simple-audio-card,name = "rockchip,rt5640-codec";
		simple-audio-card,mclk-fs = <0x100>;
		simple-audio-card,widgets = "Microphone", "Mic Jack", "Headphone", "Headphone Jack";
		simple-audio-card,routing = "Mic Jack", "MICBIAS1", "IN1P", "Mic Jack", "Headphone Jack", "HPOL", "Headphone Jack", "HPOR";

		simple-audio-card,cpu {
			sound-dai = <0xd2>;
		};

		simple-audio-card,codec {
			sound-dai = <0xd3>;
		};
	};

	spdif-sound {
		status = "okay";
		compatible = "simple-audio-card";
		simple-audio-card,name = "ROCKCHIP,SPDIF";

		simple-audio-card,cpu {
			sound-dai = <0xd4>;
		};

		simple-audio-card,codec {
			sound-dai = <0xd5>;
		};
	};

	spdif-out {
		status = "okay";
		compatible = "linux,spdif-dit";
		#sound-dai-cells = <0x00>;
		linux,phandle = <0xd5>;
		phandle = <0xd5>;
	};

	wireless-wlan {
		compatible = "wlan-platdata";
		rockchip,grf = <0x15>;
		wifi_chip_type = "ap6354";
		sdio_vref = <0x708>;
		WIFI,host_wake_irq = <0xce 0x03 0x00>;
		status = "okay";
	};

	wireless-bluetooth {
		compatible = "bluetooth-platdata";
		clocks = <0xcc 0x01>;
		clock-names = "ext_clock";
		uart_rts_gpios = <0xa7 0x13 0x01>;
		pinctrl-names = "default", "rts_gpio";
		pinctrl-0 = <0xd6>;
		pinctrl-1 = <0xd7>;
		BT,reset_gpio = <0xce 0x09 0x00>;
		BT,wake_gpio = <0xa7 0x1a 0x00>;
		BT,wake_host_irq = <0xce 0x04 0x00>;
		status = "okay";
	};

	test-power {
		status = "okay";
	};
};
